VERSION "RCM"

NS_ :

BS_:

BU_: RCM ECU DASH

BO_ 768 RM0_Outputs: 8 RCM
 SG_ RM0_CH01_Out : 0|1@1+ (1,0) [0|1] "" Vector__XXX
 SG_ RM0_CH02_Out : 1|1@1+ (1,0) [0|1] "" Vector__XXX
 SG_ RM0_CH03_Out : 2|1@1+ (1,0) [0|1] "" Vector__XXX
 SG_ RM0_CH04_Out : 3|1@1+ (1,0) [0|1] "" Vector__XXX
 SG_ RM0_CH05_Out : 4|1@1+ (1,0) [0|1] "" Vector__XXX
 SG_ RM0_CH06_Out : 5|1@1+ (1,0) [0|1] "" Vector__XXX
 SG_ RM0_CH07_Out : 6|1@1+ (1,0) [0|1] "" Vector__XXX
 SG_ RM0_CH08_Out : 7|1@1+ (1,0) [0|1] "" Vector__XXX
 SG_ RM0_CH09_Out : 8|1@1+ (1,0) [0|1] "" Vector__XXX
 SG_ RM0_CH10_Out : 9|1@1+ (1,0) [0|1] "" Vector__XXX
 SG_ RM0_CH11_Out : 10|1@1+ (1,0) [0|1] "" Vector__XXX
 SG_ RM0_CH12_Out : 11|1@1+ (1,0) [0|1] "" Vector__XXX
 SG_ RM0_CH13_Out : 12|1@1+ (1,0) [0|1] "" Vector__XXX
 SG_ RM0_CH14_Out : 13|1@1+ (1,0) [0|1] "" Vector__XXX
 SG_ RM0_CH15_Out : 14|1@1+ (1,0) [0|1] "" Vector__XXX
 SG_ RM0_CH16_Out : 15|1@1+ (1,0) [0|1] "" Vector__XXX
 SG_ RM0_CH17_Out : 16|1@1+ (1,0) [0|1] "" Vector__XXX
 SG_ RM0_CH18_Out : 17|1@1+ (1,0) [0|1] "" Vector__XXX
 SG_ RM0_CH19_Out : 18|1@1+ (1,0) [0|1] "" Vector__XXX
 SG_ RM0_CH20_Out : 19|1@1+ (1,0) [0|1] "" Vector__XXX
 SG_ RM0_CH21_Out : 20|1@1+ (1,0) [0|1] "" Vector__XXX
 SG_ RM0_OutputsEnabled : 24|1@1+ (1,0) [0|1] "" Vector__XXX
 SG_ RM0_Failsafe : 25|1@1+ (1,0) [0|1] "" Vector__XXX
 SG_ RM0_AnyFault : 26|1@1+ (1,0) [0|1] "" Vector__XXX
 SG_ RM0_ImuOk : 27|1@1+ (1,0) [0|1] "" Vector__XXX
 SG_ RM0_EepromOk : 28|1@1+ (1,0) [0|1] "" Vector__XXX
 SG_ RM0_RoleKeypad : 29|1@1+ (1,0) [0|1] "" Vector__XXX
 SG_ RM0_IgnitionOn : 30|1@1+ (1,0) [0|1] "" Vector__XXX
 SG_ RM0_Forced500k : 31|1@1+ (1,0) [0|1] "" Vector__XXX
 SG_ RM0_UptimeSec : 32|16@1+ (1,0) [0|65535] "s" Vector__XXX
 SG_ RM0_NodeId : 48|8@1+ (1,0) [0|7] "" Vector__XXX
 SG_ RM0_Seq : 56|8@1+ (1,0) [0|255] "" Vector__XXX

BO_ 769 RM0_Inputs: 8 RCM
 SG_ RM0_CH01_In : 0|1@1+ (1,0) [0|1] "" Vector__XXX
 SG_ RM0_CH02_In : 1|1@1+ (1,0) [0|1] "" Vector__XXX
 SG_ RM0_CH03_In : 2|1@1+ (1,0) [0|1] "" Vector__XXX
 SG_ RM0_CH04_In : 3|1@1+ (1,0) [0|1] "" Vector__XXX
 SG_ RM0_CH05_In : 4|1@1+ (1,0) [0|1] "" Vector__XXX
 SG_ RM0_CH06_In : 5|1@1+ (1,0) [0|1] "" Vector__XXX
 SG_ RM0_CH07_In : 6|1@1+ (1,0) [0|1] "" Vector__XXX
 SG_ RM0_CH08_In : 7|1@1+ (1,0) [0|1] "" Vector__XXX
 SG_ RM0_CH09_In : 8|1@1+ (1,0) [0|1] "" Vector__XXX
 SG_ RM0_CH10_In : 9|1@1+ (1,0) [0|1] "" Vector__XXX
 SG_ RM0_CH11_In : 10|1@1+ (1,0) [0|1] "" Vector__XXX
 SG_ RM0_CH12_In : 11|1@1+ (1,0) [0|1] "" Vector__XXX
 SG_ RM0_CH13_In : 12|1@1+ (1,0) [0|1] "" Vector__XXX
 SG_ RM0_CH14_In : 13|1@1+ (1,0) [0|1] "" Vector__XXX
 SG_ RM0_CH15_In : 14|1@1+ (1,0) [0|1] "" Vector__XXX
 SG_ RM0_CH16_In : 15|1@1+ (1,0) [0|1] "" Vector__XXX
 SG_ RM0_CH17_In : 16|1@1+ (1,0) [0|1] "" Vector__XXX
 SG_ RM0_CH18_In : 17|1@1+ (1,0) [0|1] "" Vector__XXX
 SG_ RM0_CH19_In : 18|1@1+ (1,0) [0|1] "" Vector__XXX
 SG_ RM0_CH20_In : 19|1@1+ (1,0) [0|1] "" Vector__XXX
 SG_ RM0_CH21_In : 20|1@1+ (1,0) [0|1] "" Vector__XXX
 SG_ RM0_Aux1 : 24|1@1+ (1,0) [0|1] "" Vector__XXX
 SG_ RM0_Aux2 : 25|1@1+ (1,0) [0|1] "" Vector__XXX
 SG_ RM0_Aux3 : 26|1@1+ (1,0) [0|1] "" Vector__XXX
 SG_ RM0_CH01_Sense : 32|1@1+ (1,0) [0|1] "" Vector__XXX
 SG_ RM0_CH02_Sense : 33|1@1+ (1,0) [0|1] "" Vector__XXX
 SG_ RM0_CH03_Sense : 34|1@1+ (1,0) [0|1] "" Vector__XXX
 SG_ RM0_CH04_Sense : 35|1@1+ (1,0) [0|1] "" Vector__XXX
 SG_ RM0_CH05_Sense : 36|1@1+ (1,0) [0|1] "" Vector__XXX
 SG_ RM0_CH06_Sense : 37|1@1+ (1,0) [0|1] "" Vector__XXX
 SG_ RM0_CH07_Sense : 38|1@1+ (1,0) [0|1] "" Vector__XXX
 SG_ RM0_CH08_Sense : 39|1@1+ (1,0) [0|1] "" Vector__XXX
 SG_ RM0_CH09_Sense : 40|1@1+ (1,0) [0|1] "" Vector__XXX
 SG_ RM0_CH10_Sense : 41|1@1+ (1,0) [0|1] "" Vector__XXX
 SG_ RM0_CH11_Sense : 42|1@1+ (1,0) [0|1] "" Vector__XXX
 SG_ RM0_CH12_Sense : 43|1@1+ (1,0) [0|1] "" Vector__XXX
 SG_ RM0_CH13_Sense : 44|1@1+ (1,0) [0|1] "" Vector__XXX
 SG_ RM0_CH14_Sense : 45|1@1+ (1,0) [0|1] "" Vector__XXX
 SG_ RM0_CH15_Sense : 46|1@1+ (1,0) [0|1] "" Vector__XXX
 SG_ RM0_CH16_Sense : 47|1@1+ (1,0) [0|1] "" Vector__XXX
 SG_ RM0_CH17_Sense : 48|1@1+ (1,0) [0|1] "" Vector__XXX
 SG_ RM0_CH18_Sense : 49|1@1+ (1,0) [0|1] "" Vector__XXX
 SG_ RM0_CH19_Sense : 50|1@1+ (1,0) [0|1] "" Vector__XXX
 SG_ RM0_CH20_Sense : 51|1@1+ (1,0) [0|1] "" Vector__XXX
 SG_ RM0_CH21_Sense : 52|1@1+ (1,0) [0|1] "" Vector__XXX
 SG_ RM0_InSeq : 56|8@1+ (1,0) [0|255] "" Vector__XXX

BO_ 770 RM0_Faults: 8 RCM
 SG_ RM0_CH01_Open : 0|1@1+ (1,0) [0|1] "" Vector__XXX
 SG_ RM0_CH02_Open : 1|1@1+ (1,0) [0|1] "" Vector__XXX
 SG_ RM0_CH03_Open : 2|1@1+ (1,0) [0|1] "" Vector__XXX
 SG_ RM0_CH04_Open : 3|1@1+ (1,0) [0|1] "" Vector__XXX
 SG_ RM0_CH05_Open : 4|1@1+ (1,0) [0|1] "" Vector__XXX
 SG_ RM0_CH06_Open : 5|1@1+ (1,0) [0|1] "" Vector__XXX
 SG_ RM0_CH07_Open : 6|1@1+ (1,0) [0|1] "" Vector__XXX
 SG_ RM0_CH08_Open : 7|1@1+ (1,0) [0|1] "" Vector__XXX
 SG_ RM0_CH09_Open : 8|1@1+ (1,0) [0|1] "" Vector__XXX
 SG_ RM0_CH10_Open : 9|1@1+ (1,0) [0|1] "" Vector__XXX
 SG_ RM0_CH11_Open : 10|1@1+ (1,0) [0|1] "" Vector__XXX
 SG_ RM0_CH12_Open : 11|1@1+ (1,0) [0|1] "" Vector__XXX
 SG_ RM0_CH13_Open : 12|1@1+ (1,0) [0|1] "" Vector__XXX
 SG_ RM0_CH14_Open : 13|1@1+ (1,0) [0|1] "" Vector__XXX
 SG_ RM0_CH15_Open : 14|1@1+ (1,0) [0|1] "" Vector__XXX
 SG_ RM0_CH16_Open : 15|1@1+ (1,0) [0|1] "" Vector__XXX
 SG_ RM0_CH17_Open : 16|1@1+ (1,0) [0|1] "" Vector__XXX
 SG_ RM0_CH18_Open : 17|1@1+ (1,0) [0|1] "" Vector__XXX
 SG_ RM0_CH19_Open : 18|1@1+ (1,0) [0|1] "" Vector__XXX
 SG_ RM0_CH20_Open : 19|1@1+ (1,0) [0|1] "" Vector__XXX
 SG_ RM0_CH21_Open : 20|1@1+ (1,0) [0|1] "" Vector__XXX
 SG_ RM0_CH01_Short : 24|1@1+ (1,0) [0|1] "" Vector__XXX
 SG_ RM0_CH02_Short : 25|1@1+ (1,0) [0|1] "" Vector__XXX
 SG_ RM0_CH03_Short : 26|1@1+ (1,0) [0|1] "" Vector__XXX
 SG_ RM0_CH04_Short : 27|1@1+ (1,0) [0|1] "" Vector__XXX
 SG_ RM0_CH05_Short : 28|1@1+ (1,0) [0|1] "" Vector__XXX
 SG_ RM0_CH06_Short : 29|1@1+ (1,0) [0|1] "" Vector__XXX
 SG_ RM0_CH07_Short : 30|1@1+ (1,0) [0|1] "" Vector__XXX
 SG_ RM0_CH08_Short : 31|1@1+ (1,0) [0|1] "" Vector__XXX
 SG_ RM0_CH09_Short : 32|1@1+ (1,0) [0|1] "" Vector__XXX
 SG_ RM0_CH10_Short : 33|1@1+ (1,0) [0|1] "" Vector__XXX
 SG_ RM0_CH11_Short : 34|1@1+ (1,0) [0|1] "" Vector__XXX
 SG_ RM0_CH12_Short : 35|1@1+ (1,0) [0|1] "" Vector__XXX
 SG_ RM0_CH13_Short : 36|1@1+ (1,0) [0|1] "" Vector__XXX
 SG_ RM0_CH14_Short : 37|1@1+ (1,0) [0|1] "" Vector__XXX
 SG_ RM0_CH15_Short : 38|1@1+ (1,0) [0|1] "" Vector__XXX
 SG_ RM0_CH16_Short : 39|1@1+ (1,0) [0|1] "" Vector__XXX
 SG_ RM0_CH17_Short : 40|1@1+ (1,0) [0|1] "" Vector__XXX
 SG_ RM0_CH18_Short : 41|1@1+ (1,0) [0|1] "" Vector__XXX
 SG_ RM0_CH19_Short : 42|1@1+ (1,0) [0|1] "" Vector__XXX
 SG_ RM0_CH20_Short : 43|1@1+ (1,0) [0|1] "" Vector__XXX
 SG_ RM0_CH21_Short : 44|1@1+ (1,0) [0|1] "" Vector__XXX
 SG_ RM0_FaultSeq : 56|8@1+ (1,0) [0|255] "" Vector__XXX

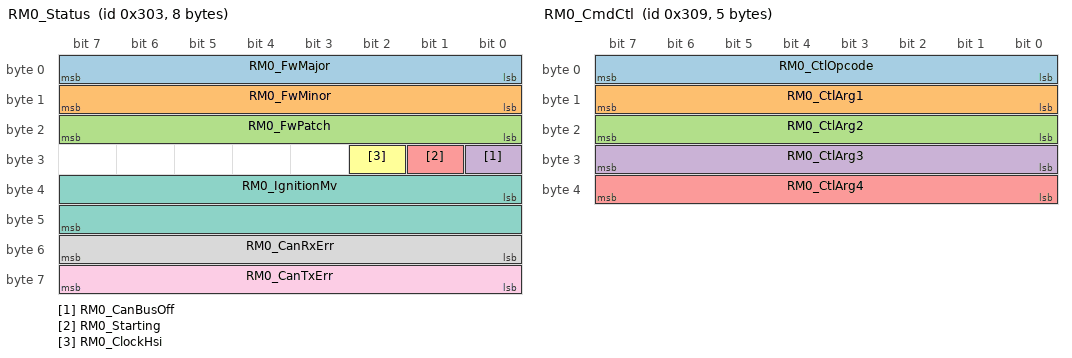
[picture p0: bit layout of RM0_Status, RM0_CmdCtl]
BO_ 771 RM0_Status: 8 RCM
 SG_ RM0_FwMajor : 0|8@1+ (1,0) [0|255] "" Vector__XXX
 SG_ RM0_FwMinor : 8|8@1+ (1,0) [0|255] "" Vector__XXX
 SG_ RM0_FwPatch : 16|8@1+ (1,0) [0|255] "" Vector__XXX
 SG_ RM0_CanBusOff : 24|1@1+ (1,0) [0|1] "" Vector__XXX
 SG_ RM0_Starting : 25|1@1+ (1,0) [0|1] "" Vector__XXX
 SG_ RM0_ClockHsi : 26|1@1+ (1,0) [0|1] "" Vector__XXX
 SG_ RM0_IgnitionMv : 32|16@1+ (1,0) [0|65535] "mV" Vector__XXX
 SG_ RM0_CanRxErr : 48|8@1+ (1,0) [0|255] "" Vector__XXX
 SG_ RM0_CanTxErr : 56|8@1+ (1,0) [0|255] "" Vector__XXX

BO_ 776 RM0_CmdSet: 6 ECU
 SG_ RM0_SetMask01 : 0|1@1+ (1,0) [0|1] "" Vector__XXX
 SG_ RM0_SetMask02 : 1|1@1+ (1,0) [0|1] "" Vector__XXX
 SG_ RM0_SetMask03 : 2|1@1+ (1,0) [0|1] "" Vector__XXX
 SG_ RM0_SetMask04 : 3|1@1+ (1,0) [0|1] "" Vector__XXX
 SG_ RM0_SetMask05 : 4|1@1+ (1,0) [0|1] "" Vector__XXX
 SG_ RM0_SetMask06 : 5|1@1+ (1,0) [0|1] "" Vector__XXX
 SG_ RM0_SetMask07 : 6|1@1+ (1,0) [0|1] "" Vector__XXX
 SG_ RM0_SetMask08 : 7|1@1+ (1,0) [0|1] "" Vector__XXX
 SG_ RM0_SetMask09 : 8|1@1+ (1,0) [0|1] "" Vector__XXX
 SG_ RM0_SetMask10 : 9|1@1+ (1,0) [0|1] "" Vector__XXX
 SG_ RM0_SetMask11 : 10|1@1+ (1,0) [0|1] "" Vector__XXX
 SG_ RM0_SetMask12 : 11|1@1+ (1,0) [0|1] "" Vector__XXX
 SG_ RM0_SetMask13 : 12|1@1+ (1,0) [0|1] "" Vector__XXX
 SG_ RM0_SetMask14 : 13|1@1+ (1,0) [0|1] "" Vector__XXX
 SG_ RM0_SetMask15 : 14|1@1+ (1,0) [0|1] "" Vector__XXX
 SG_ RM0_SetMask16 : 15|1@1+ (1,0) [0|1] "" Vector__XXX
 SG_ RM0_SetMask17 : 16|1@1+ (1,0) [0|1] "" Vector__XXX
 SG_ RM0_SetMask18 : 17|1@1+ (1,0) [0|1] "" Vector__XXX
 SG_ RM0_SetMask19 : 18|1@1+ (1,0) [0|1] "" Vector__XXX
 SG_ RM0_SetMask20 : 19|1@1+ (1,0) [0|1] "" Vector__XXX
 SG_ RM0_SetMask21 : 20|1@1+ (1,0) [0|1] "" Vector__XXX
 SG_ RM0_SetVal01 : 24|1@1+ (1,0) [0|1] "" Vector__XXX
 SG_ RM0_SetVal02 : 25|1@1+ (1,0) [0|1] "" Vector__XXX
 SG_ RM0_SetVal03 : 26|1@1+ (1,0) [0|1] "" Vector__XXX
 SG_ RM0_SetVal04 : 27|1@1+ (1,0) [0|1] "" Vector__XXX
 SG_ RM0_SetVal05 : 28|1@1+ (1,0) [0|1] "" Vector__XXX
 SG_ RM0_SetVal06 : 29|1@1+ (1,0) [0|1] "" Vector__XXX
 SG_ RM0_SetVal07 : 30|1@1+ (1,0) [0|1] "" Vector__XXX
 SG_ RM0_SetVal08 : 31|1@1+ (1,0) [0|1] "" Vector__XXX
 SG_ RM0_SetVal09 : 32|1@1+ (1,0) [0|1] "" Vector__XXX
 SG_ RM0_SetVal10 : 33|1@1+ (1,0) [0|1] "" Vector__XXX
 SG_ RM0_SetVal11 : 34|1@1+ (1,0) [0|1] "" Vector__XXX
 SG_ RM0_SetVal12 : 35|1@1+ (1,0) [0|1] "" Vector__XXX
 SG_ RM0_SetVal13 : 36|1@1+ (1,0) [0|1] "" Vector__XXX
 SG_ RM0_SetVal14 : 37|1@1+ (1,0) [0|1] "" Vector__XXX
 SG_ RM0_SetVal15 : 38|1@1+ (1,0) [0|1] "" Vector__XXX
 SG_ RM0_SetVal16 : 39|1@1+ (1,0) [0|1] "" Vector__XXX
 SG_ RM0_SetVal17 : 40|1@1+ (1,0) [0|1] "" Vector__XXX
 SG_ RM0_SetVal18 : 41|1@1+ (1,0) [0|1] "" Vector__XXX
 SG_ RM0_SetVal19 : 42|1@1+ (1,0) [0|1] "" Vector__XXX
 SG_ RM0_SetVal20 : 43|1@1+ (1,0) [0|1] "" Vector__XXX
 SG_ RM0_SetVal21 : 44|1@1+ (1,0) [0|1] "" Vector__XXX

BO_ 777 RM0_CmdCtl: 5 ECU
 SG_ RM0_CtlOpcode : 0|8@1+ (1,0) [0|255] "" Vector__XXX
 SG_ RM0_CtlArg1 : 8|8@1+ (1,0) [0|255] "" Vector__XXX
 SG_ RM0_CtlArg2 : 16|8@1+ (1,0) [0|255] "" Vector__XXX
 SG_ RM0_CtlArg3 : 24|8@1+ (1,0) [0|255] "" Vector__XXX
 SG_ RM0_CtlArg4 : 32|8@1+ (1,0) [0|255] "" Vector__XXX

BO_ 784 RM1_Outputs: 8 RCM
 SG_ RM1_CH01_Out : 0|1@1+ (1,0) [0|1] "" Vector__XXX
 SG_ RM1_CH02_Out : 1|1@1+ (1,0) [0|1] "" Vector__XXX
 SG_ RM1_CH03_Out : 2|1@1+ (1,0) [0|1] "" Vector__XXX
 SG_ RM1_CH04_Out : 3|1@1+ (1,0) [0|1] "" Vector__XXX
 SG_ RM1_CH05_Out : 4|1@1+ (1,0) [0|1] "" Vector__XXX
 SG_ RM1_CH06_Out : 5|1@1+ (1,0) [0|1] "" Vector__XXX
 SG_ RM1_CH07_Out : 6|1@1+ (1,0) [0|1] "" Vector__XXX
 SG_ RM1_CH08_Out : 7|1@1+ (1,0) [0|1] "" Vector__XXX
 SG_ RM1_CH09_Out : 8|1@1+ (1,0) [0|1] "" Vector__XXX
 SG_ RM1_CH10_Out : 9|1@1+ (1,0) [0|1] "" Vector__XXX
 SG_ RM1_CH11_Out : 10|1@1+ (1,0) [0|1] "" Vector__XXX
 SG_ RM1_CH12_Out : 11|1@1+ (1,0) [0|1] "" Vector__XXX
 SG_ RM1_CH13_Out : 12|1@1+ (1,0) [0|1] "" Vector__XXX
 SG_ RM1_CH14_Out : 13|1@1+ (1,0) [0|1] "" Vector__XXX
 SG_ RM1_CH15_Out : 14|1@1+ (1,0) [0|1] "" Vector__XXX
 SG_ RM1_CH16_Out : 15|1@1+ (1,0) [0|1] "" Vector__XXX
 SG_ RM1_CH17_Out : 16|1@1+ (1,0) [0|1] "" Vector__XXX
 SG_ RM1_CH18_Out : 17|1@1+ (1,0) [0|1] "" Vector__XXX
 SG_ RM1_CH19_Out : 18|1@1+ (1,0) [0|1] "" Vector__XXX
 SG_ RM1_CH20_Out : 19|1@1+ (1,0) [0|1] "" Vector__XXX
 SG_ RM1_CH21_Out : 20|1@1+ (1,0) [0|1] "" Vector__XXX
 SG_ RM1_OutputsEnabled : 24|1@1+ (1,0) [0|1] "" Vector__XXX
 SG_ RM1_Failsafe : 25|1@1+ (1,0) [0|1] "" Vector__XXX
 SG_ RM1_AnyFault : 26|1@1+ (1,0) [0|1] "" Vector__XXX
 SG_ RM1_ImuOk : 27|1@1+ (1,0) [0|1] "" Vector__XXX
 SG_ RM1_EepromOk : 28|1@1+ (1,0) [0|1] "" Vector__XXX
 SG_ RM1_RoleKeypad : 29|1@1+ (1,0) [0|1] "" Vector__XXX
 SG_ RM1_IgnitionOn : 30|1@1+ (1,0) [0|1] "" Vector__XXX
 SG_ RM1_Forced500k : 31|1@1+ (1,0) [0|1] "" Vector__XXX
 SG_ RM1_UptimeSec : 32|16@1+ (1,0) [0|65535] "s" Vector__XXX
 SG_ RM1_NodeId : 48|8@1+ (1,0) [0|7] "" Vector__XXX
 SG_ RM1_Seq : 56|8@1+ (1,0) [0|255] "" Vector__XXX

BO_ 785 RM1_Inputs: 8 RCM
 SG_ RM1_CH01_In : 0|1@1+ (1,0) [0|1] "" Vector__XXX
 SG_ RM1_CH02_In : 1|1@1+ (1,0) [0|1] "" Vector__XXX
 SG_ RM1_CH03_In : 2|1@1+ (1,0) [0|1] "" Vector__XXX
 SG_ RM1_CH04_In : 3|1@1+ (1,0) [0|1] "" Vector__XXX
 SG_ RM1_CH05_In : 4|1@1+ (1,0) [0|1] "" Vector__XXX
 SG_ RM1_CH06_In : 5|1@1+ (1,0) [0|1] "" Vector__XXX
 SG_ RM1_CH07_In : 6|1@1+ (1,0) [0|1] "" Vector__XXX
 SG_ RM1_CH08_In : 7|1@1+ (1,0) [0|1] "" Vector__XXX
 SG_ RM1_CH09_In : 8|1@1+ (1,0) [0|1] "" Vector__XXX
 SG_ RM1_CH10_In : 9|1@1+ (1,0) [0|1] "" Vector__XXX
 SG_ RM1_CH11_In : 10|1@1+ (1,0) [0|1] "" Vector__XXX
 SG_ RM1_CH12_In : 11|1@1+ (1,0) [0|1] "" Vector__XXX
 SG_ RM1_CH13_In : 12|1@1+ (1,0) [0|1] "" Vector__XXX
 SG_ RM1_CH14_In : 13|1@1+ (1,0) [0|1] "" Vector__XXX
 SG_ RM1_CH15_In : 14|1@1+ (1,0) [0|1] "" Vector__XXX
 SG_ RM1_CH16_In : 15|1@1+ (1,0) [0|1] "" Vector__XXX
 SG_ RM1_CH17_In : 16|1@1+ (1,0) [0|1] "" Vector__XXX
 SG_ RM1_CH18_In : 17|1@1+ (1,0) [0|1] "" Vector__XXX
 SG_ RM1_CH19_In : 18|1@1+ (1,0) [0|1] "" Vector__XXX
 SG_ RM1_CH20_In : 19|1@1+ (1,0) [0|1] "" Vector__XXX
 SG_ RM1_CH21_In : 20|1@1+ (1,0) [0|1] "" Vector__XXX
 SG_ RM1_Aux1 : 24|1@1+ (1,0) [0|1] "" Vector__XXX
 SG_ RM1_Aux2 : 25|1@1+ (1,0) [0|1] "" Vector__XXX
 SG_ RM1_Aux3 : 26|1@1+ (1,0) [0|1] "" Vector__XXX
 SG_ RM1_CH01_Sense : 32|1@1+ (1,0) [0|1] "" Vector__XXX
 SG_ RM1_CH02_Sense : 33|1@1+ (1,0) [0|1] "" Vector__XXX
 SG_ RM1_CH03_Sense : 34|1@1+ (1,0) [0|1] "" Vector__XXX
 SG_ RM1_CH04_Sense : 35|1@1+ (1,0) [0|1] "" Vector__XXX
 SG_ RM1_CH05_Sense : 36|1@1+ (1,0) [0|1] "" Vector__XXX
 SG_ RM1_CH06_Sense : 37|1@1+ (1,0) [0|1] "" Vector__XXX
 SG_ RM1_CH07_Sense : 38|1@1+ (1,0) [0|1] "" Vector__XXX
 SG_ RM1_CH08_Sense : 39|1@1+ (1,0) [0|1] "" Vector__XXX
 SG_ RM1_CH09_Sense : 40|1@1+ (1,0) [0|1] "" Vector__XXX
 SG_ RM1_CH10_Sense : 41|1@1+ (1,0) [0|1] "" Vector__XXX
 SG_ RM1_CH11_Sense : 42|1@1+ (1,0) [0|1] "" Vector__XXX
 SG_ RM1_CH12_Sense : 43|1@1+ (1,0) [0|1] "" Vector__XXX
 SG_ RM1_CH13_Sense : 44|1@1+ (1,0) [0|1] "" Vector__XXX
 SG_ RM1_CH14_Sense : 45|1@1+ (1,0) [0|1] "" Vector__XXX
 SG_ RM1_CH15_Sense : 46|1@1+ (1,0) [0|1] "" Vector__XXX
 SG_ RM1_CH16_Sense : 47|1@1+ (1,0) [0|1] "" Vector__XXX
 SG_ RM1_CH17_Sense : 48|1@1+ (1,0) [0|1] "" Vector__XXX
 SG_ RM1_CH18_Sense : 49|1@1+ (1,0) [0|1] "" Vector__XXX
 SG_ RM1_CH19_Sense : 50|1@1+ (1,0) [0|1] "" Vector__XXX
 SG_ RM1_CH20_Sense : 51|1@1+ (1,0) [0|1] "" Vector__XXX
 SG_ RM1_CH21_Sense : 52|1@1+ (1,0) [0|1] "" Vector__XXX
 SG_ RM1_InSeq : 56|8@1+ (1,0) [0|255] "" Vector__XXX

BO_ 786 RM1_Faults: 8 RCM
 SG_ RM1_CH01_Open : 0|1@1+ (1,0) [0|1] "" Vector__XXX
 SG_ RM1_CH02_Open : 1|1@1+ (1,0) [0|1] "" Vector__XXX
 SG_ RM1_CH03_Open : 2|1@1+ (1,0) [0|1] "" Vector__XXX
 SG_ RM1_CH04_Open : 3|1@1+ (1,0) [0|1] "" Vector__XXX
 SG_ RM1_CH05_Open : 4|1@1+ (1,0) [0|1] "" Vector__XXX
 SG_ RM1_CH06_Open : 5|1@1+ (1,0) [0|1] "" Vector__XXX
 SG_ RM1_CH07_Open : 6|1@1+ (1,0) [0|1] "" Vector__XXX
 SG_ RM1_CH08_Open : 7|1@1+ (1,0) [0|1] "" Vector__XXX
 SG_ RM1_CH09_Open : 8|1@1+ (1,0) [0|1] "" Vector__XXX
 SG_ RM1_CH10_Open : 9|1@1+ (1,0) [0|1] "" Vector__XXX
 SG_ RM1_CH11_Open : 10|1@1+ (1,0) [0|1] "" Vector__XXX
 SG_ RM1_CH12_Open : 11|1@1+ (1,0) [0|1] "" Vector__XXX
 SG_ RM1_CH13_Open : 12|1@1+ (1,0) [0|1] "" Vector__XXX
 SG_ RM1_CH14_Open : 13|1@1+ (1,0) [0|1] "" Vector__XXX
 SG_ RM1_CH15_Open : 14|1@1+ (1,0) [0|1] "" Vector__XXX
 SG_ RM1_CH16_Open : 15|1@1+ (1,0) [0|1] "" Vector__XXX
 SG_ RM1_CH17_Open : 16|1@1+ (1,0) [0|1] "" Vector__XXX
 SG_ RM1_CH18_Open : 17|1@1+ (1,0) [0|1] "" Vector__XXX
 SG_ RM1_CH19_Open : 18|1@1+ (1,0) [0|1] "" Vector__XXX
 SG_ RM1_CH20_Open : 19|1@1+ (1,0) [0|1] "" Vector__XXX
 SG_ RM1_CH21_Open : 20|1@1+ (1,0) [0|1] "" Vector__XXX
 SG_ RM1_CH01_Short : 24|1@1+ (1,0) [0|1] "" Vector__XXX
 SG_ RM1_CH02_Short : 25|1@1+ (1,0) [0|1] "" Vector__XXX
 SG_ RM1_CH03_Short : 26|1@1+ (1,0) [0|1] "" Vector__XXX
 SG_ RM1_CH04_Short : 27|1@1+ (1,0) [0|1] "" Vector__XXX
 SG_ RM1_CH05_Short : 28|1@1+ (1,0) [0|1] "" Vector__XXX
 SG_ RM1_CH06_Short : 29|1@1+ (1,0) [0|1] "" Vector__XXX
 SG_ RM1_CH07_Short : 30|1@1+ (1,0) [0|1] "" Vector__XXX
 SG_ RM1_CH08_Short : 31|1@1+ (1,0) [0|1] "" Vector__XXX
 SG_ RM1_CH09_Short : 32|1@1+ (1,0) [0|1] "" Vector__XXX
 SG_ RM1_CH10_Short : 33|1@1+ (1,0) [0|1] "" Vector__XXX
 SG_ RM1_CH11_Short : 34|1@1+ (1,0) [0|1] "" Vector__XXX
 SG_ RM1_CH12_Short : 35|1@1+ (1,0) [0|1] "" Vector__XXX
 SG_ RM1_CH13_Short : 36|1@1+ (1,0) [0|1] "" Vector__XXX
 SG_ RM1_CH14_Short : 37|1@1+ (1,0) [0|1] "" Vector__XXX
 SG_ RM1_CH15_Short : 38|1@1+ (1,0) [0|1] "" Vector__XXX
 SG_ RM1_CH16_Short : 39|1@1+ (1,0) [0|1] "" Vector__XXX
 SG_ RM1_CH17_Short : 40|1@1+ (1,0) [0|1] "" Vector__XXX
 SG_ RM1_CH18_Short : 41|1@1+ (1,0) [0|1] "" Vector__XXX
 SG_ RM1_CH19_Short : 42|1@1+ (1,0) [0|1] "" Vector__XXX
 SG_ RM1_CH20_Short : 43|1@1+ (1,0) [0|1] "" Vector__XXX
 SG_ RM1_CH21_Short : 44|1@1+ (1,0) [0|1] "" Vector__XXX
 SG_ RM1_FaultSeq : 56|8@1+ (1,0) [0|255] "" Vector__XXX

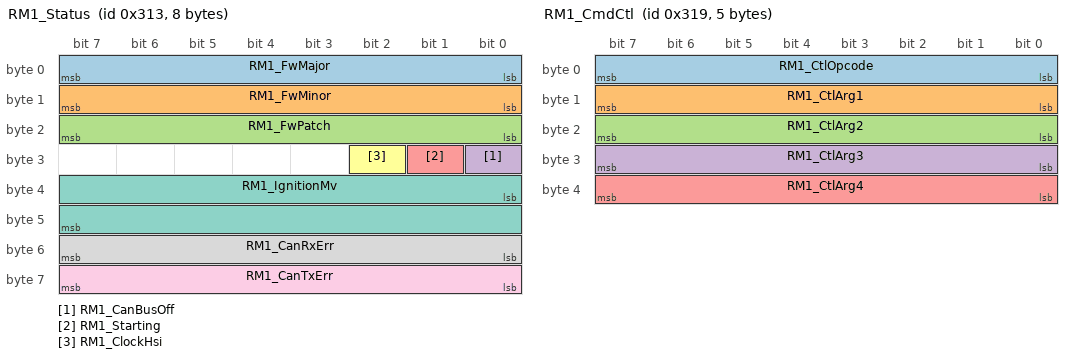
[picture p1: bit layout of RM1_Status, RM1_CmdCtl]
BO_ 787 RM1_Status: 8 RCM
 SG_ RM1_FwMajor : 0|8@1+ (1,0) [0|255] "" Vector__XXX
 SG_ RM1_FwMinor : 8|8@1+ (1,0) [0|255] "" Vector__XXX
 SG_ RM1_FwPatch : 16|8@1+ (1,0) [0|255] "" Vector__XXX
 SG_ RM1_CanBusOff : 24|1@1+ (1,0) [0|1] "" Vector__XXX
 SG_ RM1_Starting : 25|1@1+ (1,0) [0|1] "" Vector__XXX
 SG_ RM1_ClockHsi : 26|1@1+ (1,0) [0|1] "" Vector__XXX
 SG_ RM1_IgnitionMv : 32|16@1+ (1,0) [0|65535] "mV" Vector__XXX
 SG_ RM1_CanRxErr : 48|8@1+ (1,0) [0|255] "" Vector__XXX
 SG_ RM1_CanTxErr : 56|8@1+ (1,0) [0|255] "" Vector__XXX

BO_ 792 RM1_CmdSet: 6 ECU
 SG_ RM1_SetMask01 : 0|1@1+ (1,0) [0|1] "" Vector__XXX
 SG_ RM1_SetMask02 : 1|1@1+ (1,0) [0|1] "" Vector__XXX
 SG_ RM1_SetMask03 : 2|1@1+ (1,0) [0|1] "" Vector__XXX
 SG_ RM1_SetMask04 : 3|1@1+ (1,0) [0|1] "" Vector__XXX
 SG_ RM1_SetMask05 : 4|1@1+ (1,0) [0|1] "" Vector__XXX
 SG_ RM1_SetMask06 : 5|1@1+ (1,0) [0|1] "" Vector__XXX
 SG_ RM1_SetMask07 : 6|1@1+ (1,0) [0|1] "" Vector__XXX
 SG_ RM1_SetMask08 : 7|1@1+ (1,0) [0|1] "" Vector__XXX
 SG_ RM1_SetMask09 : 8|1@1+ (1,0) [0|1] "" Vector__XXX
 SG_ RM1_SetMask10 : 9|1@1+ (1,0) [0|1] "" Vector__XXX
 SG_ RM1_SetMask11 : 10|1@1+ (1,0) [0|1] "" Vector__XXX
 SG_ RM1_SetMask12 : 11|1@1+ (1,0) [0|1] "" Vector__XXX
 SG_ RM1_SetMask13 : 12|1@1+ (1,0) [0|1] "" Vector__XXX
 SG_ RM1_SetMask14 : 13|1@1+ (1,0) [0|1] "" Vector__XXX
 SG_ RM1_SetMask15 : 14|1@1+ (1,0) [0|1] "" Vector__XXX
 SG_ RM1_SetMask16 : 15|1@1+ (1,0) [0|1] "" Vector__XXX
 SG_ RM1_SetMask17 : 16|1@1+ (1,0) [0|1] "" Vector__XXX
 SG_ RM1_SetMask18 : 17|1@1+ (1,0) [0|1] "" Vector__XXX
 SG_ RM1_SetMask19 : 18|1@1+ (1,0) [0|1] "" Vector__XXX
 SG_ RM1_SetMask20 : 19|1@1+ (1,0) [0|1] "" Vector__XXX
 SG_ RM1_SetMask21 : 20|1@1+ (1,0) [0|1] "" Vector__XXX
 SG_ RM1_SetVal01 : 24|1@1+ (1,0) [0|1] "" Vector__XXX
 SG_ RM1_SetVal02 : 25|1@1+ (1,0) [0|1] "" Vector__XXX
 SG_ RM1_SetVal03 : 26|1@1+ (1,0) [0|1] "" Vector__XXX
 SG_ RM1_SetVal04 : 27|1@1+ (1,0) [0|1] "" Vector__XXX
 SG_ RM1_SetVal05 : 28|1@1+ (1,0) [0|1] "" Vector__XXX
 SG_ RM1_SetVal06 : 29|1@1+ (1,0) [0|1] "" Vector__XXX
 SG_ RM1_SetVal07 : 30|1@1+ (1,0) [0|1] "" Vector__XXX
 SG_ RM1_SetVal08 : 31|1@1+ (1,0) [0|1] "" Vector__XXX
 SG_ RM1_SetVal09 : 32|1@1+ (1,0) [0|1] "" Vector__XXX
 SG_ RM1_SetVal10 : 33|1@1+ (1,0) [0|1] "" Vector__XXX
 SG_ RM1_SetVal11 : 34|1@1+ (1,0) [0|1] "" Vector__XXX
 SG_ RM1_SetVal12 : 35|1@1+ (1,0) [0|1] "" Vector__XXX
 SG_ RM1_SetVal13 : 36|1@1+ (1,0) [0|1] "" Vector__XXX
 SG_ RM1_SetVal14 : 37|1@1+ (1,0) [0|1] "" Vector__XXX
 SG_ RM1_SetVal15 : 38|1@1+ (1,0) [0|1] "" Vector__XXX
 SG_ RM1_SetVal16 : 39|1@1+ (1,0) [0|1] "" Vector__XXX
 SG_ RM1_SetVal17 : 40|1@1+ (1,0) [0|1] "" Vector__XXX
 SG_ RM1_SetVal18 : 41|1@1+ (1,0) [0|1] "" Vector__XXX
 SG_ RM1_SetVal19 : 42|1@1+ (1,0) [0|1] "" Vector__XXX
 SG_ RM1_SetVal20 : 43|1@1+ (1,0) [0|1] "" Vector__XXX
 SG_ RM1_SetVal21 : 44|1@1+ (1,0) [0|1] "" Vector__XXX

BO_ 793 RM1_CmdCtl: 5 ECU
 SG_ RM1_CtlOpcode : 0|8@1+ (1,0) [0|255] "" Vector__XXX
 SG_ RM1_CtlArg1 : 8|8@1+ (1,0) [0|255] "" Vector__XXX
 SG_ RM1_CtlArg2 : 16|8@1+ (1,0) [0|255] "" Vector__XXX
 SG_ RM1_CtlArg3 : 24|8@1+ (1,0) [0|255] "" Vector__XXX
 SG_ RM1_CtlArg4 : 32|8@1+ (1,0) [0|255] "" Vector__XXX

BO_ 800 RM2_Outputs: 8 RCM
 SG_ RM2_CH01_Out : 0|1@1+ (1,0) [0|1] "" Vector__XXX
 SG_ RM2_CH02_Out : 1|1@1+ (1,0) [0|1] "" Vector__XXX
 SG_ RM2_CH03_Out : 2|1@1+ (1,0) [0|1] "" Vector__XXX
 SG_ RM2_CH04_Out : 3|1@1+ (1,0) [0|1] "" Vector__XXX
 SG_ RM2_CH05_Out : 4|1@1+ (1,0) [0|1] "" Vector__XXX
 SG_ RM2_CH06_Out : 5|1@1+ (1,0) [0|1] "" Vector__XXX
 SG_ RM2_CH07_Out : 6|1@1+ (1,0) [0|1] "" Vector__XXX
 SG_ RM2_CH08_Out : 7|1@1+ (1,0) [0|1] "" Vector__XXX
 SG_ RM2_CH09_Out : 8|1@1+ (1,0) [0|1] "" Vector__XXX
 SG_ RM2_CH10_Out : 9|1@1+ (1,0) [0|1] "" Vector__XXX
 SG_ RM2_CH11_Out : 10|1@1+ (1,0) [0|1] "" Vector__XXX
 SG_ RM2_CH12_Out : 11|1@1+ (1,0) [0|1] "" Vector__XXX
 SG_ RM2_CH13_Out : 12|1@1+ (1,0) [0|1] "" Vector__XXX
 SG_ RM2_CH14_Out : 13|1@1+ (1,0) [0|1] "" Vector__XXX
 SG_ RM2_CH15_Out : 14|1@1+ (1,0) [0|1] "" Vector__XXX
 SG_ RM2_CH16_Out : 15|1@1+ (1,0) [0|1] "" Vector__XXX
 SG_ RM2_CH17_Out : 16|1@1+ (1,0) [0|1] "" Vector__XXX
 SG_ RM2_CH18_Out : 17|1@1+ (1,0) [0|1] "" Vector__XXX
 SG_ RM2_CH19_Out : 18|1@1+ (1,0) [0|1] "" Vector__XXX
 SG_ RM2_CH20_Out : 19|1@1+ (1,0) [0|1] "" Vector__XXX
 SG_ RM2_CH21_Out : 20|1@1+ (1,0) [0|1] "" Vector__XXX
 SG_ RM2_OutputsEnabled : 24|1@1+ (1,0) [0|1] "" Vector__XXX
 SG_ RM2_Failsafe : 25|1@1+ (1,0) [0|1] "" Vector__XXX
 SG_ RM2_AnyFault : 26|1@1+ (1,0) [0|1] "" Vector__XXX
 SG_ RM2_ImuOk : 27|1@1+ (1,0) [0|1] "" Vector__XXX
 SG_ RM2_EepromOk : 28|1@1+ (1,0) [0|1] "" Vector__XXX
 SG_ RM2_RoleKeypad : 29|1@1+ (1,0) [0|1] "" Vector__XXX
 SG_ RM2_IgnitionOn : 30|1@1+ (1,0) [0|1] "" Vector__XXX
 SG_ RM2_Forced500k : 31|1@1+ (1,0) [0|1] "" Vector__XXX
 SG_ RM2_UptimeSec : 32|16@1+ (1,0) [0|65535] "s" Vector__XXX
 SG_ RM2_NodeId : 48|8@1+ (1,0) [0|7] "" Vector__XXX
 SG_ RM2_Seq : 56|8@1+ (1,0) [0|255] "" Vector__XXX

BO_ 801 RM2_Inputs: 8 RCM
 SG_ RM2_CH01_In : 0|1@1+ (1,0) [0|1] "" Vector__XXX
 SG_ RM2_CH02_In : 1|1@1+ (1,0) [0|1] "" Vector__XXX
 SG_ RM2_CH03_In : 2|1@1+ (1,0) [0|1] "" Vector__XXX
 SG_ RM2_CH04_In : 3|1@1+ (1,0) [0|1] "" Vector__XXX
 SG_ RM2_CH05_In : 4|1@1+ (1,0) [0|1] "" Vector__XXX
 SG_ RM2_CH06_In : 5|1@1+ (1,0) [0|1] "" Vector__XXX
 SG_ RM2_CH07_In : 6|1@1+ (1,0) [0|1] "" Vector__XXX
 SG_ RM2_CH08_In : 7|1@1+ (1,0) [0|1] "" Vector__XXX
 SG_ RM2_CH09_In : 8|1@1+ (1,0) [0|1] "" Vector__XXX
 SG_ RM2_CH10_In : 9|1@1+ (1,0) [0|1] "" Vector__XXX
 SG_ RM2_CH11_In : 10|1@1+ (1,0) [0|1] "" Vector__XXX
 SG_ RM2_CH12_In : 11|1@1+ (1,0) [0|1] "" Vector__XXX
 SG_ RM2_CH13_In : 12|1@1+ (1,0) [0|1] "" Vector__XXX
 SG_ RM2_CH14_In : 13|1@1+ (1,0) [0|1] "" Vector__XXX
 SG_ RM2_CH15_In : 14|1@1+ (1,0) [0|1] "" Vector__XXX
 SG_ RM2_CH16_In : 15|1@1+ (1,0) [0|1] "" Vector__XXX
 SG_ RM2_CH17_In : 16|1@1+ (1,0) [0|1] "" Vector__XXX
 SG_ RM2_CH18_In : 17|1@1+ (1,0) [0|1] "" Vector__XXX
 SG_ RM2_CH19_In : 18|1@1+ (1,0) [0|1] "" Vector__XXX
 SG_ RM2_CH20_In : 19|1@1+ (1,0) [0|1] "" Vector__XXX
 SG_ RM2_CH21_In : 20|1@1+ (1,0) [0|1] "" Vector__XXX
 SG_ RM2_Aux1 : 24|1@1+ (1,0) [0|1] "" Vector__XXX
 SG_ RM2_Aux2 : 25|1@1+ (1,0) [0|1] "" Vector__XXX
 SG_ RM2_Aux3 : 26|1@1+ (1,0) [0|1] "" Vector__XXX
 SG_ RM2_CH01_Sense : 32|1@1+ (1,0) [0|1] "" Vector__XXX
 SG_ RM2_CH02_Sense : 33|1@1+ (1,0) [0|1] "" Vector__XXX
 SG_ RM2_CH03_Sense : 34|1@1+ (1,0) [0|1] "" Vector__XXX
 SG_ RM2_CH04_Sense : 35|1@1+ (1,0) [0|1] "" Vector__XXX
 SG_ RM2_CH05_Sense : 36|1@1+ (1,0) [0|1] "" Vector__XXX
 SG_ RM2_CH06_Sense : 37|1@1+ (1,0) [0|1] "" Vector__XXX
 SG_ RM2_CH07_Sense : 38|1@1+ (1,0) [0|1] "" Vector__XXX
 SG_ RM2_CH08_Sense : 39|1@1+ (1,0) [0|1] "" Vector__XXX
 SG_ RM2_CH09_Sense : 40|1@1+ (1,0) [0|1] "" Vector__XXX
 SG_ RM2_CH10_Sense : 41|1@1+ (1,0) [0|1] "" Vector__XXX
 SG_ RM2_CH11_Sense : 42|1@1+ (1,0) [0|1] "" Vector__XXX
 SG_ RM2_CH12_Sense : 43|1@1+ (1,0) [0|1] "" Vector__XXX
 SG_ RM2_CH13_Sense : 44|1@1+ (1,0) [0|1] "" Vector__XXX
 SG_ RM2_CH14_Sense : 45|1@1+ (1,0) [0|1] "" Vector__XXX
 SG_ RM2_CH15_Sense : 46|1@1+ (1,0) [0|1] "" Vector__XXX
 SG_ RM2_CH16_Sense : 47|1@1+ (1,0) [0|1] "" Vector__XXX
 SG_ RM2_CH17_Sense : 48|1@1+ (1,0) [0|1] "" Vector__XXX
 SG_ RM2_CH18_Sense : 49|1@1+ (1,0) [0|1] "" Vector__XXX
 SG_ RM2_CH19_Sense : 50|1@1+ (1,0) [0|1] "" Vector__XXX
 SG_ RM2_CH20_Sense : 51|1@1+ (1,0) [0|1] "" Vector__XXX
 SG_ RM2_CH21_Sense : 52|1@1+ (1,0) [0|1] "" Vector__XXX
 SG_ RM2_InSeq : 56|8@1+ (1,0) [0|255] "" Vector__XXX

BO_ 802 RM2_Faults: 8 RCM
 SG_ RM2_CH01_Open : 0|1@1+ (1,0) [0|1] "" Vector__XXX
 SG_ RM2_CH02_Open : 1|1@1+ (1,0) [0|1] "" Vector__XXX
 SG_ RM2_CH03_Open : 2|1@1+ (1,0) [0|1] "" Vector__XXX
 SG_ RM2_CH04_Open : 3|1@1+ (1,0) [0|1] "" Vector__XXX
 SG_ RM2_CH05_Open : 4|1@1+ (1,0) [0|1] "" Vector__XXX
 SG_ RM2_CH06_Open : 5|1@1+ (1,0) [0|1] "" Vector__XXX
 SG_ RM2_CH07_Open : 6|1@1+ (1,0) [0|1] "" Vector__XXX
 SG_ RM2_CH08_Open : 7|1@1+ (1,0) [0|1] "" Vector__XXX
 SG_ RM2_CH09_Open : 8|1@1+ (1,0) [0|1] "" Vector__XXX
 SG_ RM2_CH10_Open : 9|1@1+ (1,0) [0|1] "" Vector__XXX
 SG_ RM2_CH11_Open : 10|1@1+ (1,0) [0|1] "" Vector__XXX
 SG_ RM2_CH12_Open : 11|1@1+ (1,0) [0|1] "" Vector__XXX
 SG_ RM2_CH13_Open : 12|1@1+ (1,0) [0|1] "" Vector__XXX
 SG_ RM2_CH14_Open : 13|1@1+ (1,0) [0|1] "" Vector__XXX
 SG_ RM2_CH15_Open : 14|1@1+ (1,0) [0|1] "" Vector__XXX
 SG_ RM2_CH16_Open : 15|1@1+ (1,0) [0|1] "" Vector__XXX
 SG_ RM2_CH17_Open : 16|1@1+ (1,0) [0|1] "" Vector__XXX
 SG_ RM2_CH18_Open : 17|1@1+ (1,0) [0|1] "" Vector__XXX
 SG_ RM2_CH19_Open : 18|1@1+ (1,0) [0|1] "" Vector__XXX
 SG_ RM2_CH20_Open : 19|1@1+ (1,0) [0|1] "" Vector__XXX
 SG_ RM2_CH21_Open : 20|1@1+ (1,0) [0|1] "" Vector__XXX
 SG_ RM2_CH01_Short : 24|1@1+ (1,0) [0|1] "" Vector__XXX
 SG_ RM2_CH02_Short : 25|1@1+ (1,0) [0|1] "" Vector__XXX
 SG_ RM2_CH03_Short : 26|1@1+ (1,0) [0|1] "" Vector__XXX
 SG_ RM2_CH04_Short : 27|1@1+ (1,0) [0|1] "" Vector__XXX
 SG_ RM2_CH05_Short : 28|1@1+ (1,0) [0|1] "" Vector__XXX
 SG_ RM2_CH06_Short : 29|1@1+ (1,0) [0|1] "" Vector__XXX
 SG_ RM2_CH07_Short : 30|1@1+ (1,0) [0|1] "" Vector__XXX
 SG_ RM2_CH08_Short : 31|1@1+ (1,0) [0|1] "" Vector__XXX
 SG_ RM2_CH09_Short : 32|1@1+ (1,0) [0|1] "" Vector__XXX
 SG_ RM2_CH10_Short : 33|1@1+ (1,0) [0|1] "" Vector__XXX
 SG_ RM2_CH11_Short : 34|1@1+ (1,0) [0|1] "" Vector__XXX
 SG_ RM2_CH12_Short : 35|1@1+ (1,0) [0|1] "" Vector__XXX
 SG_ RM2_CH13_Short : 36|1@1+ (1,0) [0|1] "" Vector__XXX
 SG_ RM2_CH14_Short : 37|1@1+ (1,0) [0|1] "" Vector__XXX
 SG_ RM2_CH15_Short : 38|1@1+ (1,0) [0|1] "" Vector__XXX
 SG_ RM2_CH16_Short : 39|1@1+ (1,0) [0|1] "" Vector__XXX
 SG_ RM2_CH17_Short : 40|1@1+ (1,0) [0|1] "" Vector__XXX
 SG_ RM2_CH18_Short : 41|1@1+ (1,0) [0|1] "" Vector__XXX
 SG_ RM2_CH19_Short : 42|1@1+ (1,0) [0|1] "" Vector__XXX
 SG_ RM2_CH20_Short : 43|1@1+ (1,0) [0|1] "" Vector__XXX
 SG_ RM2_CH21_Short : 44|1@1+ (1,0) [0|1] "" Vector__XXX
 SG_ RM2_FaultSeq : 56|8@1+ (1,0) [0|255] "" Vector__XXX

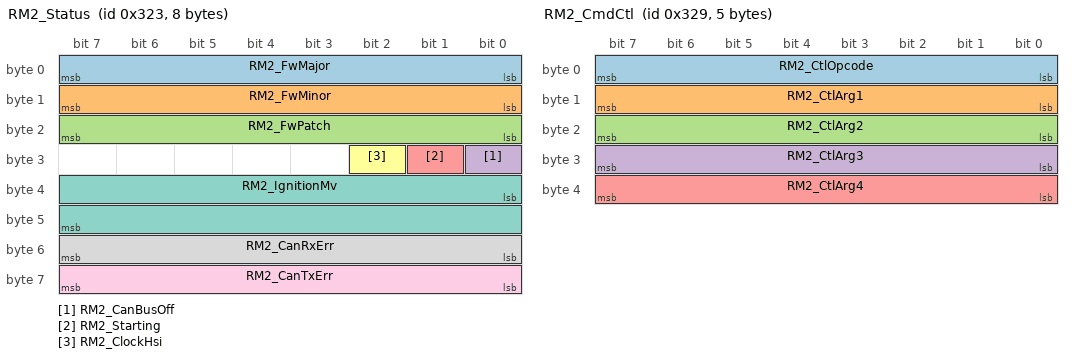
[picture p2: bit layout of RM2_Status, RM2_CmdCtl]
BO_ 803 RM2_Status: 8 RCM
 SG_ RM2_FwMajor : 0|8@1+ (1,0) [0|255] "" Vector__XXX
 SG_ RM2_FwMinor : 8|8@1+ (1,0) [0|255] "" Vector__XXX
 SG_ RM2_FwPatch : 16|8@1+ (1,0) [0|255] "" Vector__XXX
 SG_ RM2_CanBusOff : 24|1@1+ (1,0) [0|1] "" Vector__XXX
 SG_ RM2_Starting : 25|1@1+ (1,0) [0|1] "" Vector__XXX
 SG_ RM2_ClockHsi : 26|1@1+ (1,0) [0|1] "" Vector__XXX
 SG_ RM2_IgnitionMv : 32|16@1+ (1,0) [0|65535] "mV" Vector__XXX
 SG_ RM2_CanRxErr : 48|8@1+ (1,0) [0|255] "" Vector__XXX
 SG_ RM2_CanTxErr : 56|8@1+ (1,0) [0|255] "" Vector__XXX

BO_ 808 RM2_CmdSet: 6 ECU
 SG_ RM2_SetMask01 : 0|1@1+ (1,0) [0|1] "" Vector__XXX
 SG_ RM2_SetMask02 : 1|1@1+ (1,0) [0|1] "" Vector__XXX
 SG_ RM2_SetMask03 : 2|1@1+ (1,0) [0|1] "" Vector__XXX
 SG_ RM2_SetMask04 : 3|1@1+ (1,0) [0|1] "" Vector__XXX
 SG_ RM2_SetMask05 : 4|1@1+ (1,0) [0|1] "" Vector__XXX
 SG_ RM2_SetMask06 : 5|1@1+ (1,0) [0|1] "" Vector__XXX
 SG_ RM2_SetMask07 : 6|1@1+ (1,0) [0|1] "" Vector__XXX
 SG_ RM2_SetMask08 : 7|1@1+ (1,0) [0|1] "" Vector__XXX
 SG_ RM2_SetMask09 : 8|1@1+ (1,0) [0|1] "" Vector__XXX
 SG_ RM2_SetMask10 : 9|1@1+ (1,0) [0|1] "" Vector__XXX
 SG_ RM2_SetMask11 : 10|1@1+ (1,0) [0|1] "" Vector__XXX
 SG_ RM2_SetMask12 : 11|1@1+ (1,0) [0|1] "" Vector__XXX
 SG_ RM2_SetMask13 : 12|1@1+ (1,0) [0|1] "" Vector__XXX
 SG_ RM2_SetMask14 : 13|1@1+ (1,0) [0|1] "" Vector__XXX
 SG_ RM2_SetMask15 : 14|1@1+ (1,0) [0|1] "" Vector__XXX
 SG_ RM2_SetMask16 : 15|1@1+ (1,0) [0|1] "" Vector__XXX
 SG_ RM2_SetMask17 : 16|1@1+ (1,0) [0|1] "" Vector__XXX
 SG_ RM2_SetMask18 : 17|1@1+ (1,0) [0|1] "" Vector__XXX
 SG_ RM2_SetMask19 : 18|1@1+ (1,0) [0|1] "" Vector__XXX
 SG_ RM2_SetMask20 : 19|1@1+ (1,0) [0|1] "" Vector__XXX
 SG_ RM2_SetMask21 : 20|1@1+ (1,0) [0|1] "" Vector__XXX
 SG_ RM2_SetVal01 : 24|1@1+ (1,0) [0|1] "" Vector__XXX
 SG_ RM2_SetVal02 : 25|1@1+ (1,0) [0|1] "" Vector__XXX
 SG_ RM2_SetVal03 : 26|1@1+ (1,0) [0|1] "" Vector__XXX
 SG_ RM2_SetVal04 : 27|1@1+ (1,0) [0|1] "" Vector__XXX
 SG_ RM2_SetVal05 : 28|1@1+ (1,0) [0|1] "" Vector__XXX
 SG_ RM2_SetVal06 : 29|1@1+ (1,0) [0|1] "" Vector__XXX
 SG_ RM2_SetVal07 : 30|1@1+ (1,0) [0|1] "" Vector__XXX
 SG_ RM2_SetVal08 : 31|1@1+ (1,0) [0|1] "" Vector__XXX
 SG_ RM2_SetVal09 : 32|1@1+ (1,0) [0|1] "" Vector__XXX
 SG_ RM2_SetVal10 : 33|1@1+ (1,0) [0|1] "" Vector__XXX
 SG_ RM2_SetVal11 : 34|1@1+ (1,0) [0|1] "" Vector__XXX
 SG_ RM2_SetVal12 : 35|1@1+ (1,0) [0|1] "" Vector__XXX
 SG_ RM2_SetVal13 : 36|1@1+ (1,0) [0|1] "" Vector__XXX
 SG_ RM2_SetVal14 : 37|1@1+ (1,0) [0|1] "" Vector__XXX
 SG_ RM2_SetVal15 : 38|1@1+ (1,0) [0|1] "" Vector__XXX
 SG_ RM2_SetVal16 : 39|1@1+ (1,0) [0|1] "" Vector__XXX
 SG_ RM2_SetVal17 : 40|1@1+ (1,0) [0|1] "" Vector__XXX
 SG_ RM2_SetVal18 : 41|1@1+ (1,0) [0|1] "" Vector__XXX
 SG_ RM2_SetVal19 : 42|1@1+ (1,0) [0|1] "" Vector__XXX
 SG_ RM2_SetVal20 : 43|1@1+ (1,0) [0|1] "" Vector__XXX
 SG_ RM2_SetVal21 : 44|1@1+ (1,0) [0|1] "" Vector__XXX

BO_ 809 RM2_CmdCtl: 5 ECU
 SG_ RM2_CtlOpcode : 0|8@1+ (1,0) [0|255] "" Vector__XXX
 SG_ RM2_CtlArg1 : 8|8@1+ (1,0) [0|255] "" Vector__XXX
 SG_ RM2_CtlArg2 : 16|8@1+ (1,0) [0|255] "" Vector__XXX
 SG_ RM2_CtlArg3 : 24|8@1+ (1,0) [0|255] "" Vector__XXX
 SG_ RM2_CtlArg4 : 32|8@1+ (1,0) [0|255] "" Vector__XXX

BO_ 816 RM3_Outputs: 8 RCM
 SG_ RM3_CH01_Out : 0|1@1+ (1,0) [0|1] "" Vector__XXX
 SG_ RM3_CH02_Out : 1|1@1+ (1,0) [0|1] "" Vector__XXX
 SG_ RM3_CH03_Out : 2|1@1+ (1,0) [0|1] "" Vector__XXX
 SG_ RM3_CH04_Out : 3|1@1+ (1,0) [0|1] "" Vector__XXX
 SG_ RM3_CH05_Out : 4|1@1+ (1,0) [0|1] "" Vector__XXX
 SG_ RM3_CH06_Out : 5|1@1+ (1,0) [0|1] "" Vector__XXX
 SG_ RM3_CH07_Out : 6|1@1+ (1,0) [0|1] "" Vector__XXX
 SG_ RM3_CH08_Out : 7|1@1+ (1,0) [0|1] "" Vector__XXX
 SG_ RM3_CH09_Out : 8|1@1+ (1,0) [0|1] "" Vector__XXX
 SG_ RM3_CH10_Out : 9|1@1+ (1,0) [0|1] "" Vector__XXX
 SG_ RM3_CH11_Out : 10|1@1+ (1,0) [0|1] "" Vector__XXX
 SG_ RM3_CH12_Out : 11|1@1+ (1,0) [0|1] "" Vector__XXX
 SG_ RM3_CH13_Out : 12|1@1+ (1,0) [0|1] "" Vector__XXX
 SG_ RM3_CH14_Out : 13|1@1+ (1,0) [0|1] "" Vector__XXX
 SG_ RM3_CH15_Out : 14|1@1+ (1,0) [0|1] "" Vector__XXX
 SG_ RM3_CH16_Out : 15|1@1+ (1,0) [0|1] "" Vector__XXX
 SG_ RM3_CH17_Out : 16|1@1+ (1,0) [0|1] "" Vector__XXX
 SG_ RM3_CH18_Out : 17|1@1+ (1,0) [0|1] "" Vector__XXX
 SG_ RM3_CH19_Out : 18|1@1+ (1,0) [0|1] "" Vector__XXX
 SG_ RM3_CH20_Out : 19|1@1+ (1,0) [0|1] "" Vector__XXX
 SG_ RM3_CH21_Out : 20|1@1+ (1,0) [0|1] "" Vector__XXX
 SG_ RM3_OutputsEnabled : 24|1@1+ (1,0) [0|1] "" Vector__XXX
 SG_ RM3_Failsafe : 25|1@1+ (1,0) [0|1] "" Vector__XXX
 SG_ RM3_AnyFault : 26|1@1+ (1,0) [0|1] "" Vector__XXX
 SG_ RM3_ImuOk : 27|1@1+ (1,0) [0|1] "" Vector__XXX
 SG_ RM3_EepromOk : 28|1@1+ (1,0) [0|1] "" Vector__XXX
 SG_ RM3_RoleKeypad : 29|1@1+ (1,0) [0|1] "" Vector__XXX
 SG_ RM3_IgnitionOn : 30|1@1+ (1,0) [0|1] "" Vector__XXX
 SG_ RM3_Forced500k : 31|1@1+ (1,0) [0|1] "" Vector__XXX
 SG_ RM3_UptimeSec : 32|16@1+ (1,0) [0|65535] "s" Vector__XXX
 SG_ RM3_NodeId : 48|8@1+ (1,0) [0|7] "" Vector__XXX
 SG_ RM3_Seq : 56|8@1+ (1,0) [0|255] "" Vector__XXX

BO_ 817 RM3_Inputs: 8 RCM
 SG_ RM3_CH01_In : 0|1@1+ (1,0) [0|1] "" Vector__XXX
 SG_ RM3_CH02_In : 1|1@1+ (1,0) [0|1] "" Vector__XXX
 SG_ RM3_CH03_In : 2|1@1+ (1,0) [0|1] "" Vector__XXX
 SG_ RM3_CH04_In : 3|1@1+ (1,0) [0|1] "" Vector__XXX
 SG_ RM3_CH05_In : 4|1@1+ (1,0) [0|1] "" Vector__XXX
 SG_ RM3_CH06_In : 5|1@1+ (1,0) [0|1] "" Vector__XXX
 SG_ RM3_CH07_In : 6|1@1+ (1,0) [0|1] "" Vector__XXX
 SG_ RM3_CH08_In : 7|1@1+ (1,0) [0|1] "" Vector__XXX
 SG_ RM3_CH09_In : 8|1@1+ (1,0) [0|1] "" Vector__XXX
 SG_ RM3_CH10_In : 9|1@1+ (1,0) [0|1] "" Vector__XXX
 SG_ RM3_CH11_In : 10|1@1+ (1,0) [0|1] "" Vector__XXX
 SG_ RM3_CH12_In : 11|1@1+ (1,0) [0|1] "" Vector__XXX
 SG_ RM3_CH13_In : 12|1@1+ (1,0) [0|1] "" Vector__XXX
 SG_ RM3_CH14_In : 13|1@1+ (1,0) [0|1] "" Vector__XXX
 SG_ RM3_CH15_In : 14|1@1+ (1,0) [0|1] "" Vector__XXX
 SG_ RM3_CH16_In : 15|1@1+ (1,0) [0|1] "" Vector__XXX
 SG_ RM3_CH17_In : 16|1@1+ (1,0) [0|1] "" Vector__XXX
 SG_ RM3_CH18_In : 17|1@1+ (1,0) [0|1] "" Vector__XXX
 SG_ RM3_CH19_In : 18|1@1+ (1,0) [0|1] "" Vector__XXX
 SG_ RM3_CH20_In : 19|1@1+ (1,0) [0|1] "" Vector__XXX
 SG_ RM3_CH21_In : 20|1@1+ (1,0) [0|1] "" Vector__XXX
 SG_ RM3_Aux1 : 24|1@1+ (1,0) [0|1] "" Vector__XXX
 SG_ RM3_Aux2 : 25|1@1+ (1,0) [0|1] "" Vector__XXX
 SG_ RM3_Aux3 : 26|1@1+ (1,0) [0|1] "" Vector__XXX
 SG_ RM3_CH01_Sense : 32|1@1+ (1,0) [0|1] "" Vector__XXX
 SG_ RM3_CH02_Sense : 33|1@1+ (1,0) [0|1] "" Vector__XXX
 SG_ RM3_CH03_Sense : 34|1@1+ (1,0) [0|1] "" Vector__XXX
 SG_ RM3_CH04_Sense : 35|1@1+ (1,0) [0|1] "" Vector__XXX
 SG_ RM3_CH05_Sense : 36|1@1+ (1,0) [0|1] "" Vector__XXX
 SG_ RM3_CH06_Sense : 37|1@1+ (1,0) [0|1] "" Vector__XXX
 SG_ RM3_CH07_Sense : 38|1@1+ (1,0) [0|1] "" Vector__XXX
 SG_ RM3_CH08_Sense : 39|1@1+ (1,0) [0|1] "" Vector__XXX
 SG_ RM3_CH09_Sense : 40|1@1+ (1,0) [0|1] "" Vector__XXX
 SG_ RM3_CH10_Sense : 41|1@1+ (1,0) [0|1] "" Vector__XXX
 SG_ RM3_CH11_Sense : 42|1@1+ (1,0) [0|1] "" Vector__XXX
 SG_ RM3_CH12_Sense : 43|1@1+ (1,0) [0|1] "" Vector__XXX
 SG_ RM3_CH13_Sense : 44|1@1+ (1,0) [0|1] "" Vector__XXX
 SG_ RM3_CH14_Sense : 45|1@1+ (1,0) [0|1] "" Vector__XXX
 SG_ RM3_CH15_Sense : 46|1@1+ (1,0) [0|1] "" Vector__XXX
 SG_ RM3_CH16_Sense : 47|1@1+ (1,0) [0|1] "" Vector__XXX
 SG_ RM3_CH17_Sense : 48|1@1+ (1,0) [0|1] "" Vector__XXX
 SG_ RM3_CH18_Sense : 49|1@1+ (1,0) [0|1] "" Vector__XXX
 SG_ RM3_CH19_Sense : 50|1@1+ (1,0) [0|1] "" Vector__XXX
 SG_ RM3_CH20_Sense : 51|1@1+ (1,0) [0|1] "" Vector__XXX
 SG_ RM3_CH21_Sense : 52|1@1+ (1,0) [0|1] "" Vector__XXX
 SG_ RM3_InSeq : 56|8@1+ (1,0) [0|255] "" Vector__XXX

BO_ 818 RM3_Faults: 8 RCM
 SG_ RM3_CH01_Open : 0|1@1+ (1,0) [0|1] "" Vector__XXX
 SG_ RM3_CH02_Open : 1|1@1+ (1,0) [0|1] "" Vector__XXX
 SG_ RM3_CH03_Open : 2|1@1+ (1,0) [0|1] "" Vector__XXX
 SG_ RM3_CH04_Open : 3|1@1+ (1,0) [0|1] "" Vector__XXX
 SG_ RM3_CH05_Open : 4|1@1+ (1,0) [0|1] "" Vector__XXX
 SG_ RM3_CH06_Open : 5|1@1+ (1,0) [0|1] "" Vector__XXX
 SG_ RM3_CH07_Open : 6|1@1+ (1,0) [0|1] "" Vector__XXX
 SG_ RM3_CH08_Open : 7|1@1+ (1,0) [0|1] "" Vector__XXX
 SG_ RM3_CH09_Open : 8|1@1+ (1,0) [0|1] "" Vector__XXX
 SG_ RM3_CH10_Open : 9|1@1+ (1,0) [0|1] "" Vector__XXX
 SG_ RM3_CH11_Open : 10|1@1+ (1,0) [0|1] "" Vector__XXX
 SG_ RM3_CH12_Open : 11|1@1+ (1,0) [0|1] "" Vector__XXX
 SG_ RM3_CH13_Open : 12|1@1+ (1,0) [0|1] "" Vector__XXX
 SG_ RM3_CH14_Open : 13|1@1+ (1,0) [0|1] "" Vector__XXX
 SG_ RM3_CH15_Open : 14|1@1+ (1,0) [0|1] "" Vector__XXX
 SG_ RM3_CH16_Open : 15|1@1+ (1,0) [0|1] "" Vector__XXX
 SG_ RM3_CH17_Open : 16|1@1+ (1,0) [0|1] "" Vector__XXX
 SG_ RM3_CH18_Open : 17|1@1+ (1,0) [0|1] "" Vector__XXX
 SG_ RM3_CH19_Open : 18|1@1+ (1,0) [0|1] "" Vector__XXX
 SG_ RM3_CH20_Open : 19|1@1+ (1,0) [0|1] "" Vector__XXX
 SG_ RM3_CH21_Open : 20|1@1+ (1,0) [0|1] "" Vector__XXX
 SG_ RM3_CH01_Short : 24|1@1+ (1,0) [0|1] "" Vector__XXX
 SG_ RM3_CH02_Short : 25|1@1+ (1,0) [0|1] "" Vector__XXX
 SG_ RM3_CH03_Short : 26|1@1+ (1,0) [0|1] "" Vector__XXX
 SG_ RM3_CH04_Short : 27|1@1+ (1,0) [0|1] "" Vector__XXX
 SG_ RM3_CH05_Short : 28|1@1+ (1,0) [0|1] "" Vector__XXX
 SG_ RM3_CH06_Short : 29|1@1+ (1,0) [0|1] "" Vector__XXX
 SG_ RM3_CH07_Short : 30|1@1+ (1,0) [0|1] "" Vector__XXX
 SG_ RM3_CH08_Short : 31|1@1+ (1,0) [0|1] "" Vector__XXX
 SG_ RM3_CH09_Short : 32|1@1+ (1,0) [0|1] "" Vector__XXX
 SG_ RM3_CH10_Short : 33|1@1+ (1,0) [0|1] "" Vector__XXX
 SG_ RM3_CH11_Short : 34|1@1+ (1,0) [0|1] "" Vector__XXX
 SG_ RM3_CH12_Short : 35|1@1+ (1,0) [0|1] "" Vector__XXX
 SG_ RM3_CH13_Short : 36|1@1+ (1,0) [0|1] "" Vector__XXX
 SG_ RM3_CH14_Short : 37|1@1+ (1,0) [0|1] "" Vector__XXX
 SG_ RM3_CH15_Short : 38|1@1+ (1,0) [0|1] "" Vector__XXX
 SG_ RM3_CH16_Short : 39|1@1+ (1,0) [0|1] "" Vector__XXX
 SG_ RM3_CH17_Short : 40|1@1+ (1,0) [0|1] "" Vector__XXX
 SG_ RM3_CH18_Short : 41|1@1+ (1,0) [0|1] "" Vector__XXX
 SG_ RM3_CH19_Short : 42|1@1+ (1,0) [0|1] "" Vector__XXX
 SG_ RM3_CH20_Short : 43|1@1+ (1,0) [0|1] "" Vector__XXX
 SG_ RM3_CH21_Short : 44|1@1+ (1,0) [0|1] "" Vector__XXX
 SG_ RM3_FaultSeq : 56|8@1+ (1,0) [0|255] "" Vector__XXX

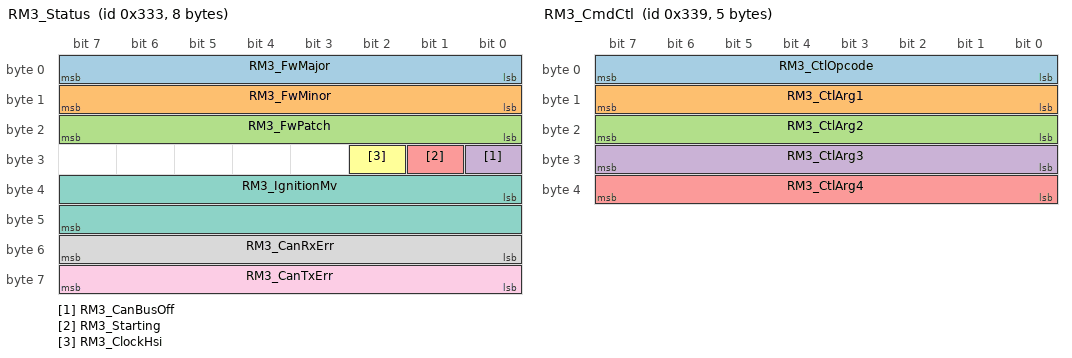
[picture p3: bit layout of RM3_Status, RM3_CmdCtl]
BO_ 819 RM3_Status: 8 RCM
 SG_ RM3_FwMajor : 0|8@1+ (1,0) [0|255] "" Vector__XXX
 SG_ RM3_FwMinor : 8|8@1+ (1,0) [0|255] "" Vector__XXX
 SG_ RM3_FwPatch : 16|8@1+ (1,0) [0|255] "" Vector__XXX
 SG_ RM3_CanBusOff : 24|1@1+ (1,0) [0|1] "" Vector__XXX
 SG_ RM3_Starting : 25|1@1+ (1,0) [0|1] "" Vector__XXX
 SG_ RM3_ClockHsi : 26|1@1+ (1,0) [0|1] "" Vector__XXX
 SG_ RM3_IgnitionMv : 32|16@1+ (1,0) [0|65535] "mV" Vector__XXX
 SG_ RM3_CanRxErr : 48|8@1+ (1,0) [0|255] "" Vector__XXX
 SG_ RM3_CanTxErr : 56|8@1+ (1,0) [0|255] "" Vector__XXX

BO_ 824 RM3_CmdSet: 6 ECU
 SG_ RM3_SetMask01 : 0|1@1+ (1,0) [0|1] "" Vector__XXX
 SG_ RM3_SetMask02 : 1|1@1+ (1,0) [0|1] "" Vector__XXX
 SG_ RM3_SetMask03 : 2|1@1+ (1,0) [0|1] "" Vector__XXX
 SG_ RM3_SetMask04 : 3|1@1+ (1,0) [0|1] "" Vector__XXX
 SG_ RM3_SetMask05 : 4|1@1+ (1,0) [0|1] "" Vector__XXX
 SG_ RM3_SetMask06 : 5|1@1+ (1,0) [0|1] "" Vector__XXX
 SG_ RM3_SetMask07 : 6|1@1+ (1,0) [0|1] "" Vector__XXX
 SG_ RM3_SetMask08 : 7|1@1+ (1,0) [0|1] "" Vector__XXX
 SG_ RM3_SetMask09 : 8|1@1+ (1,0) [0|1] "" Vector__XXX
 SG_ RM3_SetMask10 : 9|1@1+ (1,0) [0|1] "" Vector__XXX
 SG_ RM3_SetMask11 : 10|1@1+ (1,0) [0|1] "" Vector__XXX
 SG_ RM3_SetMask12 : 11|1@1+ (1,0) [0|1] "" Vector__XXX
 SG_ RM3_SetMask13 : 12|1@1+ (1,0) [0|1] "" Vector__XXX
 SG_ RM3_SetMask14 : 13|1@1+ (1,0) [0|1] "" Vector__XXX
 SG_ RM3_SetMask15 : 14|1@1+ (1,0) [0|1] "" Vector__XXX
 SG_ RM3_SetMask16 : 15|1@1+ (1,0) [0|1] "" Vector__XXX
 SG_ RM3_SetMask17 : 16|1@1+ (1,0) [0|1] "" Vector__XXX
 SG_ RM3_SetMask18 : 17|1@1+ (1,0) [0|1] "" Vector__XXX
 SG_ RM3_SetMask19 : 18|1@1+ (1,0) [0|1] "" Vector__XXX
 SG_ RM3_SetMask20 : 19|1@1+ (1,0) [0|1] "" Vector__XXX
 SG_ RM3_SetMask21 : 20|1@1+ (1,0) [0|1] "" Vector__XXX
 SG_ RM3_SetVal01 : 24|1@1+ (1,0) [0|1] "" Vector__XXX
 SG_ RM3_SetVal02 : 25|1@1+ (1,0) [0|1] "" Vector__XXX
 SG_ RM3_SetVal03 : 26|1@1+ (1,0) [0|1] "" Vector__XXX
 SG_ RM3_SetVal04 : 27|1@1+ (1,0) [0|1] "" Vector__XXX
 SG_ RM3_SetVal05 : 28|1@1+ (1,0) [0|1] "" Vector__XXX
 SG_ RM3_SetVal06 : 29|1@1+ (1,0) [0|1] "" Vector__XXX
 SG_ RM3_SetVal07 : 30|1@1+ (1,0) [0|1] "" Vector__XXX
 SG_ RM3_SetVal08 : 31|1@1+ (1,0) [0|1] "" Vector__XXX
 SG_ RM3_SetVal09 : 32|1@1+ (1,0) [0|1] "" Vector__XXX
 SG_ RM3_SetVal10 : 33|1@1+ (1,0) [0|1] "" Vector__XXX
 SG_ RM3_SetVal11 : 34|1@1+ (1,0) [0|1] "" Vector__XXX
 SG_ RM3_SetVal12 : 35|1@1+ (1,0) [0|1] "" Vector__XXX
 SG_ RM3_SetVal13 : 36|1@1+ (1,0) [0|1] "" Vector__XXX
 SG_ RM3_SetVal14 : 37|1@1+ (1,0) [0|1] "" Vector__XXX
 SG_ RM3_SetVal15 : 38|1@1+ (1,0) [0|1] "" Vector__XXX
 SG_ RM3_SetVal16 : 39|1@1+ (1,0) [0|1] "" Vector__XXX
 SG_ RM3_SetVal17 : 40|1@1+ (1,0) [0|1] "" Vector__XXX
 SG_ RM3_SetVal18 : 41|1@1+ (1,0) [0|1] "" Vector__XXX
 SG_ RM3_SetVal19 : 42|1@1+ (1,0) [0|1] "" Vector__XXX
 SG_ RM3_SetVal20 : 43|1@1+ (1,0) [0|1] "" Vector__XXX
 SG_ RM3_SetVal21 : 44|1@1+ (1,0) [0|1] "" Vector__XXX

BO_ 825 RM3_CmdCtl: 5 ECU
 SG_ RM3_CtlOpcode : 0|8@1+ (1,0) [0|255] "" Vector__XXX
 SG_ RM3_CtlArg1 : 8|8@1+ (1,0) [0|255] "" Vector__XXX
 SG_ RM3_CtlArg2 : 16|8@1+ (1,0) [0|255] "" Vector__XXX
 SG_ RM3_CtlArg3 : 24|8@1+ (1,0) [0|255] "" Vector__XXX
 SG_ RM3_CtlArg4 : 32|8@1+ (1,0) [0|255] "" Vector__XXX

BO_ 832 KP0_Outputs: 8 RCM
 SG_ KP0_CH01_Out : 0|1@1+ (1,0) [0|1] "" Vector__XXX
 SG_ KP0_CH02_Out : 1|1@1+ (1,0) [0|1] "" Vector__XXX
 SG_ KP0_CH03_Out : 2|1@1+ (1,0) [0|1] "" Vector__XXX
 SG_ KP0_CH04_Out : 3|1@1+ (1,0) [0|1] "" Vector__XXX
 SG_ KP0_CH05_Out : 4|1@1+ (1,0) [0|1] "" Vector__XXX
 SG_ KP0_CH06_Out : 5|1@1+ (1,0) [0|1] "" Vector__XXX
 SG_ KP0_CH07_Out : 6|1@1+ (1,0) [0|1] "" Vector__XXX
 SG_ KP0_CH08_Out : 7|1@1+ (1,0) [0|1] "" Vector__XXX
 SG_ KP0_CH09_Out : 8|1@1+ (1,0) [0|1] "" Vector__XXX
 SG_ KP0_CH10_Out : 9|1@1+ (1,0) [0|1] "" Vector__XXX
 SG_ KP0_CH11_Out : 10|1@1+ (1,0) [0|1] "" Vector__XXX
 SG_ KP0_CH12_Out : 11|1@1+ (1,0) [0|1] "" Vector__XXX
 SG_ KP0_CH13_Out : 12|1@1+ (1,0) [0|1] "" Vector__XXX
 SG_ KP0_CH14_Out : 13|1@1+ (1,0) [0|1] "" Vector__XXX
 SG_ KP0_CH15_Out : 14|1@1+ (1,0) [0|1] "" Vector__XXX
 SG_ KP0_CH16_Out : 15|1@1+ (1,0) [0|1] "" Vector__XXX
 SG_ KP0_CH17_Out : 16|1@1+ (1,0) [0|1] "" Vector__XXX
 SG_ KP0_CH18_Out : 17|1@1+ (1,0) [0|1] "" Vector__XXX
 SG_ KP0_CH19_Out : 18|1@1+ (1,0) [0|1] "" Vector__XXX
 SG_ KP0_CH20_Out : 19|1@1+ (1,0) [0|1] "" Vector__XXX
 SG_ KP0_CH21_Out : 20|1@1+ (1,0) [0|1] "" Vector__XXX
 SG_ KP0_OutputsEnabled : 24|1@1+ (1,0) [0|1] "" Vector__XXX
 SG_ KP0_Failsafe : 25|1@1+ (1,0) [0|1] "" Vector__XXX
 SG_ KP0_AnyFault : 26|1@1+ (1,0) [0|1] "" Vector__XXX
 SG_ KP0_ImuOk : 27|1@1+ (1,0) [0|1] "" Vector__XXX
 SG_ KP0_EepromOk : 28|1@1+ (1,0) [0|1] "" Vector__XXX
 SG_ KP0_RoleKeypad : 29|1@1+ (1,0) [0|1] "" Vector__XXX
 SG_ KP0_IgnitionOn : 30|1@1+ (1,0) [0|1] "" Vector__XXX
 SG_ KP0_Forced500k : 31|1@1+ (1,0) [0|1] "" Vector__XXX
 SG_ KP0_UptimeSec : 32|16@1+ (1,0) [0|65535] "s" Vector__XXX
 SG_ KP0_NodeId : 48|8@1+ (1,0) [0|7] "" Vector__XXX
 SG_ KP0_Seq : 56|8@1+ (1,0) [0|255] "" Vector__XXX

BO_ 833 KP0_Inputs: 8 RCM
 SG_ KP0_CH01_In : 0|1@1+ (1,0) [0|1] "" Vector__XXX
 SG_ KP0_CH02_In : 1|1@1+ (1,0) [0|1] "" Vector__XXX
 SG_ KP0_CH03_In : 2|1@1+ (1,0) [0|1] "" Vector__XXX
 SG_ KP0_CH04_In : 3|1@1+ (1,0) [0|1] "" Vector__XXX
 SG_ KP0_CH05_In : 4|1@1+ (1,0) [0|1] "" Vector__XXX
 SG_ KP0_CH06_In : 5|1@1+ (1,0) [0|1] "" Vector__XXX
 SG_ KP0_CH07_In : 6|1@1+ (1,0) [0|1] "" Vector__XXX
 SG_ KP0_CH08_In : 7|1@1+ (1,0) [0|1] "" Vector__XXX
 SG_ KP0_CH09_In : 8|1@1+ (1,0) [0|1] "" Vector__XXX
 SG_ KP0_CH10_In : 9|1@1+ (1,0) [0|1] "" Vector__XXX
 SG_ KP0_CH11_In : 10|1@1+ (1,0) [0|1] "" Vector__XXX
 SG_ KP0_CH12_In : 11|1@1+ (1,0) [0|1] "" Vector__XXX
 SG_ KP0_CH13_In : 12|1@1+ (1,0) [0|1] "" Vector__XXX
 SG_ KP0_CH14_In : 13|1@1+ (1,0) [0|1] "" Vector__XXX
 SG_ KP0_CH15_In : 14|1@1+ (1,0) [0|1] "" Vector__XXX
 SG_ KP0_CH16_In : 15|1@1+ (1,0) [0|1] "" Vector__XXX
 SG_ KP0_CH17_In : 16|1@1+ (1,0) [0|1] "" Vector__XXX
 SG_ KP0_CH18_In : 17|1@1+ (1,0) [0|1] "" Vector__XXX
 SG_ KP0_CH19_In : 18|1@1+ (1,0) [0|1] "" Vector__XXX
 SG_ KP0_CH20_In : 19|1@1+ (1,0) [0|1] "" Vector__XXX
 SG_ KP0_CH21_In : 20|1@1+ (1,0) [0|1] "" Vector__XXX
 SG_ KP0_Aux1 : 24|1@1+ (1,0) [0|1] "" Vector__XXX
 SG_ KP0_Aux2 : 25|1@1+ (1,0) [0|1] "" Vector__XXX
 SG_ KP0_Aux3 : 26|1@1+ (1,0) [0|1] "" Vector__XXX
 SG_ KP0_CH01_Sense : 32|1@1+ (1,0) [0|1] "" Vector__XXX
 SG_ KP0_CH02_Sense : 33|1@1+ (1,0) [0|1] "" Vector__XXX
 SG_ KP0_CH03_Sense : 34|1@1+ (1,0) [0|1] "" Vector__XXX
 SG_ KP0_CH04_Sense : 35|1@1+ (1,0) [0|1] "" Vector__XXX
 SG_ KP0_CH05_Sense : 36|1@1+ (1,0) [0|1] "" Vector__XXX
 SG_ KP0_CH06_Sense : 37|1@1+ (1,0) [0|1] "" Vector__XXX
 SG_ KP0_CH07_Sense : 38|1@1+ (1,0) [0|1] "" Vector__XXX
 SG_ KP0_CH08_Sense : 39|1@1+ (1,0) [0|1] "" Vector__XXX
 SG_ KP0_CH09_Sense : 40|1@1+ (1,0) [0|1] "" Vector__XXX
 SG_ KP0_CH10_Sense : 41|1@1+ (1,0) [0|1] "" Vector__XXX
 SG_ KP0_CH11_Sense : 42|1@1+ (1,0) [0|1] "" Vector__XXX
 SG_ KP0_CH12_Sense : 43|1@1+ (1,0) [0|1] "" Vector__XXX
 SG_ KP0_CH13_Sense : 44|1@1+ (1,0) [0|1] "" Vector__XXX
 SG_ KP0_CH14_Sense : 45|1@1+ (1,0) [0|1] "" Vector__XXX
 SG_ KP0_CH15_Sense : 46|1@1+ (1,0) [0|1] "" Vector__XXX
 SG_ KP0_CH16_Sense : 47|1@1+ (1,0) [0|1] "" Vector__XXX
 SG_ KP0_CH17_Sense : 48|1@1+ (1,0) [0|1] "" Vector__XXX
 SG_ KP0_CH18_Sense : 49|1@1+ (1,0) [0|1] "" Vector__XXX
 SG_ KP0_CH19_Sense : 50|1@1+ (1,0) [0|1] "" Vector__XXX
 SG_ KP0_CH20_Sense : 51|1@1+ (1,0) [0|1] "" Vector__XXX
 SG_ KP0_CH21_Sense : 52|1@1+ (1,0) [0|1] "" Vector__XXX
 SG_ KP0_InSeq : 56|8@1+ (1,0) [0|255] "" Vector__XXX

BO_ 834 KP0_Faults: 8 RCM
 SG_ KP0_CH01_Open : 0|1@1+ (1,0) [0|1] "" Vector__XXX
 SG_ KP0_CH02_Open : 1|1@1+ (1,0) [0|1] "" Vector__XXX
 SG_ KP0_CH03_Open : 2|1@1+ (1,0) [0|1] "" Vector__XXX
 SG_ KP0_CH04_Open : 3|1@1+ (1,0) [0|1] "" Vector__XXX
 SG_ KP0_CH05_Open : 4|1@1+ (1,0) [0|1] "" Vector__XXX
 SG_ KP0_CH06_Open : 5|1@1+ (1,0) [0|1] "" Vector__XXX
 SG_ KP0_CH07_Open : 6|1@1+ (1,0) [0|1] "" Vector__XXX
 SG_ KP0_CH08_Open : 7|1@1+ (1,0) [0|1] "" Vector__XXX
 SG_ KP0_CH09_Open : 8|1@1+ (1,0) [0|1] "" Vector__XXX
 SG_ KP0_CH10_Open : 9|1@1+ (1,0) [0|1] "" Vector__XXX
 SG_ KP0_CH11_Open : 10|1@1+ (1,0) [0|1] "" Vector__XXX
 SG_ KP0_CH12_Open : 11|1@1+ (1,0) [0|1] "" Vector__XXX
 SG_ KP0_CH13_Open : 12|1@1+ (1,0) [0|1] "" Vector__XXX
 SG_ KP0_CH14_Open : 13|1@1+ (1,0) [0|1] "" Vector__XXX
 SG_ KP0_CH15_Open : 14|1@1+ (1,0) [0|1] "" Vector__XXX
 SG_ KP0_CH16_Open : 15|1@1+ (1,0) [0|1] "" Vector__XXX
 SG_ KP0_CH17_Open : 16|1@1+ (1,0) [0|1] "" Vector__XXX
 SG_ KP0_CH18_Open : 17|1@1+ (1,0) [0|1] "" Vector__XXX
 SG_ KP0_CH19_Open : 18|1@1+ (1,0) [0|1] "" Vector__XXX
 SG_ KP0_CH20_Open : 19|1@1+ (1,0) [0|1] "" Vector__XXX
 SG_ KP0_CH21_Open : 20|1@1+ (1,0) [0|1] "" Vector__XXX
 SG_ KP0_CH01_Short : 24|1@1+ (1,0) [0|1] "" Vector__XXX
 SG_ KP0_CH02_Short : 25|1@1+ (1,0) [0|1] "" Vector__XXX
 SG_ KP0_CH03_Short : 26|1@1+ (1,0) [0|1] "" Vector__XXX
 SG_ KP0_CH04_Short : 27|1@1+ (1,0) [0|1] "" Vector__XXX
 SG_ KP0_CH05_Short : 28|1@1+ (1,0) [0|1] "" Vector__XXX
 SG_ KP0_CH06_Short : 29|1@1+ (1,0) [0|1] "" Vector__XXX
 SG_ KP0_CH07_Short : 30|1@1+ (1,0) [0|1] "" Vector__XXX
 SG_ KP0_CH08_Short : 31|1@1+ (1,0) [0|1] "" Vector__XXX
 SG_ KP0_CH09_Short : 32|1@1+ (1,0) [0|1] "" Vector__XXX
 SG_ KP0_CH10_Short : 33|1@1+ (1,0) [0|1] "" Vector__XXX
 SG_ KP0_CH11_Short : 34|1@1+ (1,0) [0|1] "" Vector__XXX
 SG_ KP0_CH12_Short : 35|1@1+ (1,0) [0|1] "" Vector__XXX
 SG_ KP0_CH13_Short : 36|1@1+ (1,0) [0|1] "" Vector__XXX
 SG_ KP0_CH14_Short : 37|1@1+ (1,0) [0|1] "" Vector__XXX
 SG_ KP0_CH15_Short : 38|1@1+ (1,0) [0|1] "" Vector__XXX
 SG_ KP0_CH16_Short : 39|1@1+ (1,0) [0|1] "" Vector__XXX
 SG_ KP0_CH17_Short : 40|1@1+ (1,0) [0|1] "" Vector__XXX
 SG_ KP0_CH18_Short : 41|1@1+ (1,0) [0|1] "" Vector__XXX
 SG_ KP0_CH19_Short : 42|1@1+ (1,0) [0|1] "" Vector__XXX
 SG_ KP0_CH20_Short : 43|1@1+ (1,0) [0|1] "" Vector__XXX
 SG_ KP0_CH21_Short : 44|1@1+ (1,0) [0|1] "" Vector__XXX
 SG_ KP0_FaultSeq : 56|8@1+ (1,0) [0|255] "" Vector__XXX

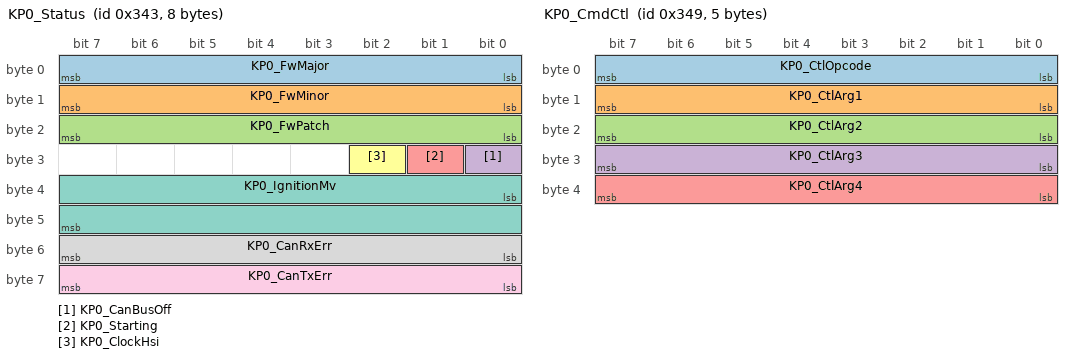
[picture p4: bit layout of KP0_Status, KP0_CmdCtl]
BO_ 835 KP0_Status: 8 RCM
 SG_ KP0_FwMajor : 0|8@1+ (1,0) [0|255] "" Vector__XXX
 SG_ KP0_FwMinor : 8|8@1+ (1,0) [0|255] "" Vector__XXX
 SG_ KP0_FwPatch : 16|8@1+ (1,0) [0|255] "" Vector__XXX
 SG_ KP0_CanBusOff : 24|1@1+ (1,0) [0|1] "" Vector__XXX
 SG_ KP0_Starting : 25|1@1+ (1,0) [0|1] "" Vector__XXX
 SG_ KP0_ClockHsi : 26|1@1+ (1,0) [0|1] "" Vector__XXX
 SG_ KP0_IgnitionMv : 32|16@1+ (1,0) [0|65535] "mV" Vector__XXX
 SG_ KP0_CanRxErr : 48|8@1+ (1,0) [0|255] "" Vector__XXX
 SG_ KP0_CanTxErr : 56|8@1+ (1,0) [0|255] "" Vector__XXX

BO_ 840 KP0_CmdSet: 6 ECU
 SG_ KP0_SetMask01 : 0|1@1+ (1,0) [0|1] "" Vector__XXX
 SG_ KP0_SetMask02 : 1|1@1+ (1,0) [0|1] "" Vector__XXX
 SG_ KP0_SetMask03 : 2|1@1+ (1,0) [0|1] "" Vector__XXX
 SG_ KP0_SetMask04 : 3|1@1+ (1,0) [0|1] "" Vector__XXX
 SG_ KP0_SetMask05 : 4|1@1+ (1,0) [0|1] "" Vector__XXX
 SG_ KP0_SetMask06 : 5|1@1+ (1,0) [0|1] "" Vector__XXX
 SG_ KP0_SetMask07 : 6|1@1+ (1,0) [0|1] "" Vector__XXX
 SG_ KP0_SetMask08 : 7|1@1+ (1,0) [0|1] "" Vector__XXX
 SG_ KP0_SetMask09 : 8|1@1+ (1,0) [0|1] "" Vector__XXX
 SG_ KP0_SetMask10 : 9|1@1+ (1,0) [0|1] "" Vector__XXX
 SG_ KP0_SetMask11 : 10|1@1+ (1,0) [0|1] "" Vector__XXX
 SG_ KP0_SetMask12 : 11|1@1+ (1,0) [0|1] "" Vector__XXX
 SG_ KP0_SetMask13 : 12|1@1+ (1,0) [0|1] "" Vector__XXX
 SG_ KP0_SetMask14 : 13|1@1+ (1,0) [0|1] "" Vector__XXX
 SG_ KP0_SetMask15 : 14|1@1+ (1,0) [0|1] "" Vector__XXX
 SG_ KP0_SetMask16 : 15|1@1+ (1,0) [0|1] "" Vector__XXX
 SG_ KP0_SetMask17 : 16|1@1+ (1,0) [0|1] "" Vector__XXX
 SG_ KP0_SetMask18 : 17|1@1+ (1,0) [0|1] "" Vector__XXX
 SG_ KP0_SetMask19 : 18|1@1+ (1,0) [0|1] "" Vector__XXX
 SG_ KP0_SetMask20 : 19|1@1+ (1,0) [0|1] "" Vector__XXX
 SG_ KP0_SetMask21 : 20|1@1+ (1,0) [0|1] "" Vector__XXX
 SG_ KP0_SetVal01 : 24|1@1+ (1,0) [0|1] "" Vector__XXX
 SG_ KP0_SetVal02 : 25|1@1+ (1,0) [0|1] "" Vector__XXX
 SG_ KP0_SetVal03 : 26|1@1+ (1,0) [0|1] "" Vector__XXX
 SG_ KP0_SetVal04 : 27|1@1+ (1,0) [0|1] "" Vector__XXX
 SG_ KP0_SetVal05 : 28|1@1+ (1,0) [0|1] "" Vector__XXX
 SG_ KP0_SetVal06 : 29|1@1+ (1,0) [0|1] "" Vector__XXX
 SG_ KP0_SetVal07 : 30|1@1+ (1,0) [0|1] "" Vector__XXX
 SG_ KP0_SetVal08 : 31|1@1+ (1,0) [0|1] "" Vector__XXX
 SG_ KP0_SetVal09 : 32|1@1+ (1,0) [0|1] "" Vector__XXX
 SG_ KP0_SetVal10 : 33|1@1+ (1,0) [0|1] "" Vector__XXX
 SG_ KP0_SetVal11 : 34|1@1+ (1,0) [0|1] "" Vector__XXX
 SG_ KP0_SetVal12 : 35|1@1+ (1,0) [0|1] "" Vector__XXX
 SG_ KP0_SetVal13 : 36|1@1+ (1,0) [0|1] "" Vector__XXX
 SG_ KP0_SetVal14 : 37|1@1+ (1,0) [0|1] "" Vector__XXX
 SG_ KP0_SetVal15 : 38|1@1+ (1,0) [0|1] "" Vector__XXX
 SG_ KP0_SetVal16 : 39|1@1+ (1,0) [0|1] "" Vector__XXX
 SG_ KP0_SetVal17 : 40|1@1+ (1,0) [0|1] "" Vector__XXX
 SG_ KP0_SetVal18 : 41|1@1+ (1,0) [0|1] "" Vector__XXX
 SG_ KP0_SetVal19 : 42|1@1+ (1,0) [0|1] "" Vector__XXX
 SG_ KP0_SetVal20 : 43|1@1+ (1,0) [0|1] "" Vector__XXX
 SG_ KP0_SetVal21 : 44|1@1+ (1,0) [0|1] "" Vector__XXX

BO_ 841 KP0_CmdCtl: 5 ECU
 SG_ KP0_CtlOpcode : 0|8@1+ (1,0) [0|255] "" Vector__XXX
 SG_ KP0_CtlArg1 : 8|8@1+ (1,0) [0|255] "" Vector__XXX
 SG_ KP0_CtlArg2 : 16|8@1+ (1,0) [0|255] "" Vector__XXX
 SG_ KP0_CtlArg3 : 24|8@1+ (1,0) [0|255] "" Vector__XXX
 SG_ KP0_CtlArg4 : 32|8@1+ (1,0) [0|255] "" Vector__XXX

BO_ 848 KP1_Outputs: 8 RCM
 SG_ KP1_CH01_Out : 0|1@1+ (1,0) [0|1] "" Vector__XXX
 SG_ KP1_CH02_Out : 1|1@1+ (1,0) [0|1] "" Vector__XXX
 SG_ KP1_CH03_Out : 2|1@1+ (1,0) [0|1] "" Vector__XXX
 SG_ KP1_CH04_Out : 3|1@1+ (1,0) [0|1] "" Vector__XXX
 SG_ KP1_CH05_Out : 4|1@1+ (1,0) [0|1] "" Vector__XXX
 SG_ KP1_CH06_Out : 5|1@1+ (1,0) [0|1] "" Vector__XXX
 SG_ KP1_CH07_Out : 6|1@1+ (1,0) [0|1] "" Vector__XXX
 SG_ KP1_CH08_Out : 7|1@1+ (1,0) [0|1] "" Vector__XXX
 SG_ KP1_CH09_Out : 8|1@1+ (1,0) [0|1] "" Vector__XXX
 SG_ KP1_CH10_Out : 9|1@1+ (1,0) [0|1] "" Vector__XXX
 SG_ KP1_CH11_Out : 10|1@1+ (1,0) [0|1] "" Vector__XXX
 SG_ KP1_CH12_Out : 11|1@1+ (1,0) [0|1] "" Vector__XXX
 SG_ KP1_CH13_Out : 12|1@1+ (1,0) [0|1] "" Vector__XXX
 SG_ KP1_CH14_Out : 13|1@1+ (1,0) [0|1] "" Vector__XXX
 SG_ KP1_CH15_Out : 14|1@1+ (1,0) [0|1] "" Vector__XXX
 SG_ KP1_CH16_Out : 15|1@1+ (1,0) [0|1] "" Vector__XXX
 SG_ KP1_CH17_Out : 16|1@1+ (1,0) [0|1] "" Vector__XXX
 SG_ KP1_CH18_Out : 17|1@1+ (1,0) [0|1] "" Vector__XXX
 SG_ KP1_CH19_Out : 18|1@1+ (1,0) [0|1] "" Vector__XXX
 SG_ KP1_CH20_Out : 19|1@1+ (1,0) [0|1] "" Vector__XXX
 SG_ KP1_CH21_Out : 20|1@1+ (1,0) [0|1] "" Vector__XXX
 SG_ KP1_OutputsEnabled : 24|1@1+ (1,0) [0|1] "" Vector__XXX
 SG_ KP1_Failsafe : 25|1@1+ (1,0) [0|1] "" Vector__XXX
 SG_ KP1_AnyFault : 26|1@1+ (1,0) [0|1] "" Vector__XXX
 SG_ KP1_ImuOk : 27|1@1+ (1,0) [0|1] "" Vector__XXX
 SG_ KP1_EepromOk : 28|1@1+ (1,0) [0|1] "" Vector__XXX
 SG_ KP1_RoleKeypad : 29|1@1+ (1,0) [0|1] "" Vector__XXX
 SG_ KP1_IgnitionOn : 30|1@1+ (1,0) [0|1] "" Vector__XXX
 SG_ KP1_Forced500k : 31|1@1+ (1,0) [0|1] "" Vector__XXX
 SG_ KP1_UptimeSec : 32|16@1+ (1,0) [0|65535] "s" Vector__XXX
 SG_ KP1_NodeId : 48|8@1+ (1,0) [0|7] "" Vector__XXX
 SG_ KP1_Seq : 56|8@1+ (1,0) [0|255] "" Vector__XXX

BO_ 849 KP1_Inputs: 8 RCM
 SG_ KP1_CH01_In : 0|1@1+ (1,0) [0|1] "" Vector__XXX
 SG_ KP1_CH02_In : 1|1@1+ (1,0) [0|1] "" Vector__XXX
 SG_ KP1_CH03_In : 2|1@1+ (1,0) [0|1] "" Vector__XXX
 SG_ KP1_CH04_In : 3|1@1+ (1,0) [0|1] "" Vector__XXX
 SG_ KP1_CH05_In : 4|1@1+ (1,0) [0|1] "" Vector__XXX
 SG_ KP1_CH06_In : 5|1@1+ (1,0) [0|1] "" Vector__XXX
 SG_ KP1_CH07_In : 6|1@1+ (1,0) [0|1] "" Vector__XXX
 SG_ KP1_CH08_In : 7|1@1+ (1,0) [0|1] "" Vector__XXX
 SG_ KP1_CH09_In : 8|1@1+ (1,0) [0|1] "" Vector__XXX
 SG_ KP1_CH10_In : 9|1@1+ (1,0) [0|1] "" Vector__XXX
 SG_ KP1_CH11_In : 10|1@1+ (1,0) [0|1] "" Vector__XXX
 SG_ KP1_CH12_In : 11|1@1+ (1,0) [0|1] "" Vector__XXX
 SG_ KP1_CH13_In : 12|1@1+ (1,0) [0|1] "" Vector__XXX
 SG_ KP1_CH14_In : 13|1@1+ (1,0) [0|1] "" Vector__XXX
 SG_ KP1_CH15_In : 14|1@1+ (1,0) [0|1] "" Vector__XXX
 SG_ KP1_CH16_In : 15|1@1+ (1,0) [0|1] "" Vector__XXX
 SG_ KP1_CH17_In : 16|1@1+ (1,0) [0|1] "" Vector__XXX
 SG_ KP1_CH18_In : 17|1@1+ (1,0) [0|1] "" Vector__XXX
 SG_ KP1_CH19_In : 18|1@1+ (1,0) [0|1] "" Vector__XXX
 SG_ KP1_CH20_In : 19|1@1+ (1,0) [0|1] "" Vector__XXX
 SG_ KP1_CH21_In : 20|1@1+ (1,0) [0|1] "" Vector__XXX
 SG_ KP1_Aux1 : 24|1@1+ (1,0) [0|1] "" Vector__XXX
 SG_ KP1_Aux2 : 25|1@1+ (1,0) [0|1] "" Vector__XXX
 SG_ KP1_Aux3 : 26|1@1+ (1,0) [0|1] "" Vector__XXX
 SG_ KP1_CH01_Sense : 32|1@1+ (1,0) [0|1] "" Vector__XXX
 SG_ KP1_CH02_Sense : 33|1@1+ (1,0) [0|1] "" Vector__XXX
 SG_ KP1_CH03_Sense : 34|1@1+ (1,0) [0|1] "" Vector__XXX
 SG_ KP1_CH04_Sense : 35|1@1+ (1,0) [0|1] "" Vector__XXX
 SG_ KP1_CH05_Sense : 36|1@1+ (1,0) [0|1] "" Vector__XXX
 SG_ KP1_CH06_Sense : 37|1@1+ (1,0) [0|1] "" Vector__XXX
 SG_ KP1_CH07_Sense : 38|1@1+ (1,0) [0|1] "" Vector__XXX
 SG_ KP1_CH08_Sense : 39|1@1+ (1,0) [0|1] "" Vector__XXX
 SG_ KP1_CH09_Sense : 40|1@1+ (1,0) [0|1] "" Vector__XXX
 SG_ KP1_CH10_Sense : 41|1@1+ (1,0) [0|1] "" Vector__XXX
 SG_ KP1_CH11_Sense : 42|1@1+ (1,0) [0|1] "" Vector__XXX
 SG_ KP1_CH12_Sense : 43|1@1+ (1,0) [0|1] "" Vector__XXX
 SG_ KP1_CH13_Sense : 44|1@1+ (1,0) [0|1] "" Vector__XXX
 SG_ KP1_CH14_Sense : 45|1@1+ (1,0) [0|1] "" Vector__XXX
 SG_ KP1_CH15_Sense : 46|1@1+ (1,0) [0|1] "" Vector__XXX
 SG_ KP1_CH16_Sense : 47|1@1+ (1,0) [0|1] "" Vector__XXX
 SG_ KP1_CH17_Sense : 48|1@1+ (1,0) [0|1] "" Vector__XXX
 SG_ KP1_CH18_Sense : 49|1@1+ (1,0) [0|1] "" Vector__XXX
 SG_ KP1_CH19_Sense : 50|1@1+ (1,0) [0|1] "" Vector__XXX
 SG_ KP1_CH20_Sense : 51|1@1+ (1,0) [0|1] "" Vector__XXX
 SG_ KP1_CH21_Sense : 52|1@1+ (1,0) [0|1] "" Vector__XXX
 SG_ KP1_InSeq : 56|8@1+ (1,0) [0|255] "" Vector__XXX

BO_ 850 KP1_Faults: 8 RCM
 SG_ KP1_CH01_Open : 0|1@1+ (1,0) [0|1] "" Vector__XXX
 SG_ KP1_CH02_Open : 1|1@1+ (1,0) [0|1] "" Vector__XXX
 SG_ KP1_CH03_Open : 2|1@1+ (1,0) [0|1] "" Vector__XXX
 SG_ KP1_CH04_Open : 3|1@1+ (1,0) [0|1] "" Vector__XXX
 SG_ KP1_CH05_Open : 4|1@1+ (1,0) [0|1] "" Vector__XXX
 SG_ KP1_CH06_Open : 5|1@1+ (1,0) [0|1] "" Vector__XXX
 SG_ KP1_CH07_Open : 6|1@1+ (1,0) [0|1] "" Vector__XXX
 SG_ KP1_CH08_Open : 7|1@1+ (1,0) [0|1] "" Vector__XXX
 SG_ KP1_CH09_Open : 8|1@1+ (1,0) [0|1] "" Vector__XXX
 SG_ KP1_CH10_Open : 9|1@1+ (1,0) [0|1] "" Vector__XXX
 SG_ KP1_CH11_Open : 10|1@1+ (1,0) [0|1] "" Vector__XXX
 SG_ KP1_CH12_Open : 11|1@1+ (1,0) [0|1] "" Vector__XXX
 SG_ KP1_CH13_Open : 12|1@1+ (1,0) [0|1] "" Vector__XXX
 SG_ KP1_CH14_Open : 13|1@1+ (1,0) [0|1] "" Vector__XXX
 SG_ KP1_CH15_Open : 14|1@1+ (1,0) [0|1] "" Vector__XXX
 SG_ KP1_CH16_Open : 15|1@1+ (1,0) [0|1] "" Vector__XXX
 SG_ KP1_CH17_Open : 16|1@1+ (1,0) [0|1] "" Vector__XXX
 SG_ KP1_CH18_Open : 17|1@1+ (1,0) [0|1] "" Vector__XXX
 SG_ KP1_CH19_Open : 18|1@1+ (1,0) [0|1] "" Vector__XXX
 SG_ KP1_CH20_Open : 19|1@1+ (1,0) [0|1] "" Vector__XXX
 SG_ KP1_CH21_Open : 20|1@1+ (1,0) [0|1] "" Vector__XXX
 SG_ KP1_CH01_Short : 24|1@1+ (1,0) [0|1] "" Vector__XXX
 SG_ KP1_CH02_Short : 25|1@1+ (1,0) [0|1] "" Vector__XXX
 SG_ KP1_CH03_Short : 26|1@1+ (1,0) [0|1] "" Vector__XXX
 SG_ KP1_CH04_Short : 27|1@1+ (1,0) [0|1] "" Vector__XXX
 SG_ KP1_CH05_Short : 28|1@1+ (1,0) [0|1] "" Vector__XXX
 SG_ KP1_CH06_Short : 29|1@1+ (1,0) [0|1] "" Vector__XXX
 SG_ KP1_CH07_Short : 30|1@1+ (1,0) [0|1] "" Vector__XXX
 SG_ KP1_CH08_Short : 31|1@1+ (1,0) [0|1] "" Vector__XXX
 SG_ KP1_CH09_Short : 32|1@1+ (1,0) [0|1] "" Vector__XXX
 SG_ KP1_CH10_Short : 33|1@1+ (1,0) [0|1] "" Vector__XXX
 SG_ KP1_CH11_Short : 34|1@1+ (1,0) [0|1] "" Vector__XXX
 SG_ KP1_CH12_Short : 35|1@1+ (1,0) [0|1] "" Vector__XXX
 SG_ KP1_CH13_Short : 36|1@1+ (1,0) [0|1] "" Vector__XXX
 SG_ KP1_CH14_Short : 37|1@1+ (1,0) [0|1] "" Vector__XXX
 SG_ KP1_CH15_Short : 38|1@1+ (1,0) [0|1] "" Vector__XXX
 SG_ KP1_CH16_Short : 39|1@1+ (1,0) [0|1] "" Vector__XXX
 SG_ KP1_CH17_Short : 40|1@1+ (1,0) [0|1] "" Vector__XXX
 SG_ KP1_CH18_Short : 41|1@1+ (1,0) [0|1] "" Vector__XXX
 SG_ KP1_CH19_Short : 42|1@1+ (1,0) [0|1] "" Vector__XXX
 SG_ KP1_CH20_Short : 43|1@1+ (1,0) [0|1] "" Vector__XXX
 SG_ KP1_CH21_Short : 44|1@1+ (1,0) [0|1] "" Vector__XXX
 SG_ KP1_FaultSeq : 56|8@1+ (1,0) [0|255] "" Vector__XXX

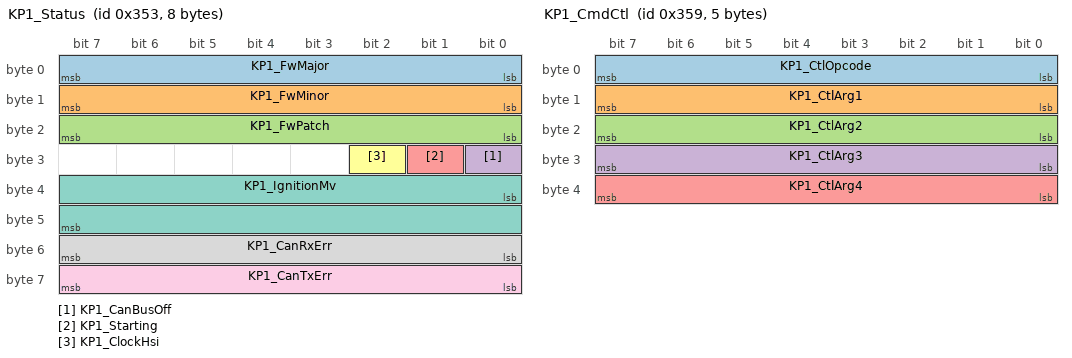
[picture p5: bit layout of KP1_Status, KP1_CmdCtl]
BO_ 851 KP1_Status: 8 RCM
 SG_ KP1_FwMajor : 0|8@1+ (1,0) [0|255] "" Vector__XXX
 SG_ KP1_FwMinor : 8|8@1+ (1,0) [0|255] "" Vector__XXX
 SG_ KP1_FwPatch : 16|8@1+ (1,0) [0|255] "" Vector__XXX
 SG_ KP1_CanBusOff : 24|1@1+ (1,0) [0|1] "" Vector__XXX
 SG_ KP1_Starting : 25|1@1+ (1,0) [0|1] "" Vector__XXX
 SG_ KP1_ClockHsi : 26|1@1+ (1,0) [0|1] "" Vector__XXX
 SG_ KP1_IgnitionMv : 32|16@1+ (1,0) [0|65535] "mV" Vector__XXX
 SG_ KP1_CanRxErr : 48|8@1+ (1,0) [0|255] "" Vector__XXX
 SG_ KP1_CanTxErr : 56|8@1+ (1,0) [0|255] "" Vector__XXX

BO_ 856 KP1_CmdSet: 6 ECU
 SG_ KP1_SetMask01 : 0|1@1+ (1,0) [0|1] "" Vector__XXX
 SG_ KP1_SetMask02 : 1|1@1+ (1,0) [0|1] "" Vector__XXX
 SG_ KP1_SetMask03 : 2|1@1+ (1,0) [0|1] "" Vector__XXX
 SG_ KP1_SetMask04 : 3|1@1+ (1,0) [0|1] "" Vector__XXX
 SG_ KP1_SetMask05 : 4|1@1+ (1,0) [0|1] "" Vector__XXX
 SG_ KP1_SetMask06 : 5|1@1+ (1,0) [0|1] "" Vector__XXX
 SG_ KP1_SetMask07 : 6|1@1+ (1,0) [0|1] "" Vector__XXX
 SG_ KP1_SetMask08 : 7|1@1+ (1,0) [0|1] "" Vector__XXX
 SG_ KP1_SetMask09 : 8|1@1+ (1,0) [0|1] "" Vector__XXX
 SG_ KP1_SetMask10 : 9|1@1+ (1,0) [0|1] "" Vector__XXX
 SG_ KP1_SetMask11 : 10|1@1+ (1,0) [0|1] "" Vector__XXX
 SG_ KP1_SetMask12 : 11|1@1+ (1,0) [0|1] "" Vector__XXX
 SG_ KP1_SetMask13 : 12|1@1+ (1,0) [0|1] "" Vector__XXX
 SG_ KP1_SetMask14 : 13|1@1+ (1,0) [0|1] "" Vector__XXX
 SG_ KP1_SetMask15 : 14|1@1+ (1,0) [0|1] "" Vector__XXX
 SG_ KP1_SetMask16 : 15|1@1+ (1,0) [0|1] "" Vector__XXX
 SG_ KP1_SetMask17 : 16|1@1+ (1,0) [0|1] "" Vector__XXX
 SG_ KP1_SetMask18 : 17|1@1+ (1,0) [0|1] "" Vector__XXX
 SG_ KP1_SetMask19 : 18|1@1+ (1,0) [0|1] "" Vector__XXX
 SG_ KP1_SetMask20 : 19|1@1+ (1,0) [0|1] "" Vector__XXX
 SG_ KP1_SetMask21 : 20|1@1+ (1,0) [0|1] "" Vector__XXX
 SG_ KP1_SetVal01 : 24|1@1+ (1,0) [0|1] "" Vector__XXX
 SG_ KP1_SetVal02 : 25|1@1+ (1,0) [0|1] "" Vector__XXX
 SG_ KP1_SetVal03 : 26|1@1+ (1,0) [0|1] "" Vector__XXX
 SG_ KP1_SetVal04 : 27|1@1+ (1,0) [0|1] "" Vector__XXX
 SG_ KP1_SetVal05 : 28|1@1+ (1,0) [0|1] "" Vector__XXX
 SG_ KP1_SetVal06 : 29|1@1+ (1,0) [0|1] "" Vector__XXX
 SG_ KP1_SetVal07 : 30|1@1+ (1,0) [0|1] "" Vector__XXX
 SG_ KP1_SetVal08 : 31|1@1+ (1,0) [0|1] "" Vector__XXX
 SG_ KP1_SetVal09 : 32|1@1+ (1,0) [0|1] "" Vector__XXX
 SG_ KP1_SetVal10 : 33|1@1+ (1,0) [0|1] "" Vector__XXX
 SG_ KP1_SetVal11 : 34|1@1+ (1,0) [0|1] "" Vector__XXX
 SG_ KP1_SetVal12 : 35|1@1+ (1,0) [0|1] "" Vector__XXX
 SG_ KP1_SetVal13 : 36|1@1+ (1,0) [0|1] "" Vector__XXX
 SG_ KP1_SetVal14 : 37|1@1+ (1,0) [0|1] "" Vector__XXX
 SG_ KP1_SetVal15 : 38|1@1+ (1,0) [0|1] "" Vector__XXX
 SG_ KP1_SetVal16 : 39|1@1+ (1,0) [0|1] "" Vector__XXX
 SG_ KP1_SetVal17 : 40|1@1+ (1,0) [0|1] "" Vector__XXX
 SG_ KP1_SetVal18 : 41|1@1+ (1,0) [0|1] "" Vector__XXX
 SG_ KP1_SetVal19 : 42|1@1+ (1,0) [0|1] "" Vector__XXX
 SG_ KP1_SetVal20 : 43|1@1+ (1,0) [0|1] "" Vector__XXX
 SG_ KP1_SetVal21 : 44|1@1+ (1,0) [0|1] "" Vector__XXX

BO_ 857 KP1_CmdCtl: 5 ECU
 SG_ KP1_CtlOpcode : 0|8@1+ (1,0) [0|255] "" Vector__XXX
 SG_ KP1_CtlArg1 : 8|8@1+ (1,0) [0|255] "" Vector__XXX
 SG_ KP1_CtlArg2 : 16|8@1+ (1,0) [0|255] "" Vector__XXX
 SG_ KP1_CtlArg3 : 24|8@1+ (1,0) [0|255] "" Vector__XXX
 SG_ KP1_CtlArg4 : 32|8@1+ (1,0) [0|255] "" Vector__XXX

BO_ 864 KP2_Outputs: 8 RCM
 SG_ KP2_CH01_Out : 0|1@1+ (1,0) [0|1] "" Vector__XXX
 SG_ KP2_CH02_Out : 1|1@1+ (1,0) [0|1] "" Vector__XXX
 SG_ KP2_CH03_Out : 2|1@1+ (1,0) [0|1] "" Vector__XXX
 SG_ KP2_CH04_Out : 3|1@1+ (1,0) [0|1] "" Vector__XXX
 SG_ KP2_CH05_Out : 4|1@1+ (1,0) [0|1] "" Vector__XXX
 SG_ KP2_CH06_Out : 5|1@1+ (1,0) [0|1] "" Vector__XXX
 SG_ KP2_CH07_Out : 6|1@1+ (1,0) [0|1] "" Vector__XXX
 SG_ KP2_CH08_Out : 7|1@1+ (1,0) [0|1] "" Vector__XXX
 SG_ KP2_CH09_Out : 8|1@1+ (1,0) [0|1] "" Vector__XXX
 SG_ KP2_CH10_Out : 9|1@1+ (1,0) [0|1] "" Vector__XXX
 SG_ KP2_CH11_Out : 10|1@1+ (1,0) [0|1] "" Vector__XXX
 SG_ KP2_CH12_Out : 11|1@1+ (1,0) [0|1] "" Vector__XXX
 SG_ KP2_CH13_Out : 12|1@1+ (1,0) [0|1] "" Vector__XXX
 SG_ KP2_CH14_Out : 13|1@1+ (1,0) [0|1] "" Vector__XXX
 SG_ KP2_CH15_Out : 14|1@1+ (1,0) [0|1] "" Vector__XXX
 SG_ KP2_CH16_Out : 15|1@1+ (1,0) [0|1] "" Vector__XXX
 SG_ KP2_CH17_Out : 16|1@1+ (1,0) [0|1] "" Vector__XXX
 SG_ KP2_CH18_Out : 17|1@1+ (1,0) [0|1] "" Vector__XXX
 SG_ KP2_CH19_Out : 18|1@1+ (1,0) [0|1] "" Vector__XXX
 SG_ KP2_CH20_Out : 19|1@1+ (1,0) [0|1] "" Vector__XXX
 SG_ KP2_CH21_Out : 20|1@1+ (1,0) [0|1] "" Vector__XXX
 SG_ KP2_OutputsEnabled : 24|1@1+ (1,0) [0|1] "" Vector__XXX
 SG_ KP2_Failsafe : 25|1@1+ (1,0) [0|1] "" Vector__XXX
 SG_ KP2_AnyFault : 26|1@1+ (1,0) [0|1] "" Vector__XXX
 SG_ KP2_ImuOk : 27|1@1+ (1,0) [0|1] "" Vector__XXX
 SG_ KP2_EepromOk : 28|1@1+ (1,0) [0|1] "" Vector__XXX
 SG_ KP2_RoleKeypad : 29|1@1+ (1,0) [0|1] "" Vector__XXX
 SG_ KP2_IgnitionOn : 30|1@1+ (1,0) [0|1] "" Vector__XXX
 SG_ KP2_Forced500k : 31|1@1+ (1,0) [0|1] "" Vector__XXX
 SG_ KP2_UptimeSec : 32|16@1+ (1,0) [0|65535] "s" Vector__XXX
 SG_ KP2_NodeId : 48|8@1+ (1,0) [0|7] "" Vector__XXX
 SG_ KP2_Seq : 56|8@1+ (1,0) [0|255] "" Vector__XXX

BO_ 865 KP2_Inputs: 8 RCM
 SG_ KP2_CH01_In : 0|1@1+ (1,0) [0|1] "" Vector__XXX
 SG_ KP2_CH02_In : 1|1@1+ (1,0) [0|1] "" Vector__XXX
 SG_ KP2_CH03_In : 2|1@1+ (1,0) [0|1] "" Vector__XXX
 SG_ KP2_CH04_In : 3|1@1+ (1,0) [0|1] "" Vector__XXX
 SG_ KP2_CH05_In : 4|1@1+ (1,0) [0|1] "" Vector__XXX
 SG_ KP2_CH06_In : 5|1@1+ (1,0) [0|1] "" Vector__XXX
 SG_ KP2_CH07_In : 6|1@1+ (1,0) [0|1] "" Vector__XXX
 SG_ KP2_CH08_In : 7|1@1+ (1,0) [0|1] "" Vector__XXX
 SG_ KP2_CH09_In : 8|1@1+ (1,0) [0|1] "" Vector__XXX
 SG_ KP2_CH10_In : 9|1@1+ (1,0) [0|1] "" Vector__XXX
 SG_ KP2_CH11_In : 10|1@1+ (1,0) [0|1] "" Vector__XXX
 SG_ KP2_CH12_In : 11|1@1+ (1,0) [0|1] "" Vector__XXX
 SG_ KP2_CH13_In : 12|1@1+ (1,0) [0|1] "" Vector__XXX
 SG_ KP2_CH14_In : 13|1@1+ (1,0) [0|1] "" Vector__XXX
 SG_ KP2_CH15_In : 14|1@1+ (1,0) [0|1] "" Vector__XXX
 SG_ KP2_CH16_In : 15|1@1+ (1,0) [0|1] "" Vector__XXX
 SG_ KP2_CH17_In : 16|1@1+ (1,0) [0|1] "" Vector__XXX
 SG_ KP2_CH18_In : 17|1@1+ (1,0) [0|1] "" Vector__XXX
 SG_ KP2_CH19_In : 18|1@1+ (1,0) [0|1] "" Vector__XXX
 SG_ KP2_CH20_In : 19|1@1+ (1,0) [0|1] "" Vector__XXX
 SG_ KP2_CH21_In : 20|1@1+ (1,0) [0|1] "" Vector__XXX
 SG_ KP2_Aux1 : 24|1@1+ (1,0) [0|1] "" Vector__XXX
 SG_ KP2_Aux2 : 25|1@1+ (1,0) [0|1] "" Vector__XXX
 SG_ KP2_Aux3 : 26|1@1+ (1,0) [0|1] "" Vector__XXX
 SG_ KP2_CH01_Sense : 32|1@1+ (1,0) [0|1] "" Vector__XXX
 SG_ KP2_CH02_Sense : 33|1@1+ (1,0) [0|1] "" Vector__XXX
 SG_ KP2_CH03_Sense : 34|1@1+ (1,0) [0|1] "" Vector__XXX
 SG_ KP2_CH04_Sense : 35|1@1+ (1,0) [0|1] "" Vector__XXX
 SG_ KP2_CH05_Sense : 36|1@1+ (1,0) [0|1] "" Vector__XXX
 SG_ KP2_CH06_Sense : 37|1@1+ (1,0) [0|1] "" Vector__XXX
 SG_ KP2_CH07_Sense : 38|1@1+ (1,0) [0|1] "" Vector__XXX
 SG_ KP2_CH08_Sense : 39|1@1+ (1,0) [0|1] "" Vector__XXX
 SG_ KP2_CH09_Sense : 40|1@1+ (1,0) [0|1] "" Vector__XXX
 SG_ KP2_CH10_Sense : 41|1@1+ (1,0) [0|1] "" Vector__XXX
 SG_ KP2_CH11_Sense : 42|1@1+ (1,0) [0|1] "" Vector__XXX
 SG_ KP2_CH12_Sense : 43|1@1+ (1,0) [0|1] "" Vector__XXX
 SG_ KP2_CH13_Sense : 44|1@1+ (1,0) [0|1] "" Vector__XXX
 SG_ KP2_CH14_Sense : 45|1@1+ (1,0) [0|1] "" Vector__XXX
 SG_ KP2_CH15_Sense : 46|1@1+ (1,0) [0|1] "" Vector__XXX
 SG_ KP2_CH16_Sense : 47|1@1+ (1,0) [0|1] "" Vector__XXX
 SG_ KP2_CH17_Sense : 48|1@1+ (1,0) [0|1] "" Vector__XXX
 SG_ KP2_CH18_Sense : 49|1@1+ (1,0) [0|1] "" Vector__XXX
 SG_ KP2_CH19_Sense : 50|1@1+ (1,0) [0|1] "" Vector__XXX
 SG_ KP2_CH20_Sense : 51|1@1+ (1,0) [0|1] "" Vector__XXX
 SG_ KP2_CH21_Sense : 52|1@1+ (1,0) [0|1] "" Vector__XXX
 SG_ KP2_InSeq : 56|8@1+ (1,0) [0|255] "" Vector__XXX

BO_ 866 KP2_Faults: 8 RCM
 SG_ KP2_CH01_Open : 0|1@1+ (1,0) [0|1] "" Vector__XXX
 SG_ KP2_CH02_Open : 1|1@1+ (1,0) [0|1] "" Vector__XXX
 SG_ KP2_CH03_Open : 2|1@1+ (1,0) [0|1] "" Vector__XXX
 SG_ KP2_CH04_Open : 3|1@1+ (1,0) [0|1] "" Vector__XXX
 SG_ KP2_CH05_Open : 4|1@1+ (1,0) [0|1] "" Vector__XXX
 SG_ KP2_CH06_Open : 5|1@1+ (1,0) [0|1] "" Vector__XXX
 SG_ KP2_CH07_Open : 6|1@1+ (1,0) [0|1] "" Vector__XXX
 SG_ KP2_CH08_Open : 7|1@1+ (1,0) [0|1] "" Vector__XXX
 SG_ KP2_CH09_Open : 8|1@1+ (1,0) [0|1] "" Vector__XXX
 SG_ KP2_CH10_Open : 9|1@1+ (1,0) [0|1] "" Vector__XXX
 SG_ KP2_CH11_Open : 10|1@1+ (1,0) [0|1] "" Vector__XXX
 SG_ KP2_CH12_Open : 11|1@1+ (1,0) [0|1] "" Vector__XXX
 SG_ KP2_CH13_Open : 12|1@1+ (1,0) [0|1] "" Vector__XXX
 SG_ KP2_CH14_Open : 13|1@1+ (1,0) [0|1] "" Vector__XXX
 SG_ KP2_CH15_Open : 14|1@1+ (1,0) [0|1] "" Vector__XXX
 SG_ KP2_CH16_Open : 15|1@1+ (1,0) [0|1] "" Vector__XXX
 SG_ KP2_CH17_Open : 16|1@1+ (1,0) [0|1] "" Vector__XXX
 SG_ KP2_CH18_Open : 17|1@1+ (1,0) [0|1] "" Vector__XXX
 SG_ KP2_CH19_Open : 18|1@1+ (1,0) [0|1] "" Vector__XXX
 SG_ KP2_CH20_Open : 19|1@1+ (1,0) [0|1] "" Vector__XXX
 SG_ KP2_CH21_Open : 20|1@1+ (1,0) [0|1] "" Vector__XXX
 SG_ KP2_CH01_Short : 24|1@1+ (1,0) [0|1] "" Vector__XXX
 SG_ KP2_CH02_Short : 25|1@1+ (1,0) [0|1] "" Vector__XXX
 SG_ KP2_CH03_Short : 26|1@1+ (1,0) [0|1] "" Vector__XXX
 SG_ KP2_CH04_Short : 27|1@1+ (1,0) [0|1] "" Vector__XXX
 SG_ KP2_CH05_Short : 28|1@1+ (1,0) [0|1] "" Vector__XXX
 SG_ KP2_CH06_Short : 29|1@1+ (1,0) [0|1] "" Vector__XXX
 SG_ KP2_CH07_Short : 30|1@1+ (1,0) [0|1] "" Vector__XXX
 SG_ KP2_CH08_Short : 31|1@1+ (1,0) [0|1] "" Vector__XXX
 SG_ KP2_CH09_Short : 32|1@1+ (1,0) [0|1] "" Vector__XXX
 SG_ KP2_CH10_Short : 33|1@1+ (1,0) [0|1] "" Vector__XXX
 SG_ KP2_CH11_Short : 34|1@1+ (1,0) [0|1] "" Vector__XXX
 SG_ KP2_CH12_Short : 35|1@1+ (1,0) [0|1] "" Vector__XXX
 SG_ KP2_CH13_Short : 36|1@1+ (1,0) [0|1] "" Vector__XXX
 SG_ KP2_CH14_Short : 37|1@1+ (1,0) [0|1] "" Vector__XXX
 SG_ KP2_CH15_Short : 38|1@1+ (1,0) [0|1] "" Vector__XXX
 SG_ KP2_CH16_Short : 39|1@1+ (1,0) [0|1] "" Vector__XXX
 SG_ KP2_CH17_Short : 40|1@1+ (1,0) [0|1] "" Vector__XXX
 SG_ KP2_CH18_Short : 41|1@1+ (1,0) [0|1] "" Vector__XXX
 SG_ KP2_CH19_Short : 42|1@1+ (1,0) [0|1] "" Vector__XXX
 SG_ KP2_CH20_Short : 43|1@1+ (1,0) [0|1] "" Vector__XXX
 SG_ KP2_CH21_Short : 44|1@1+ (1,0) [0|1] "" Vector__XXX
 SG_ KP2_FaultSeq : 56|8@1+ (1,0) [0|255] "" Vector__XXX

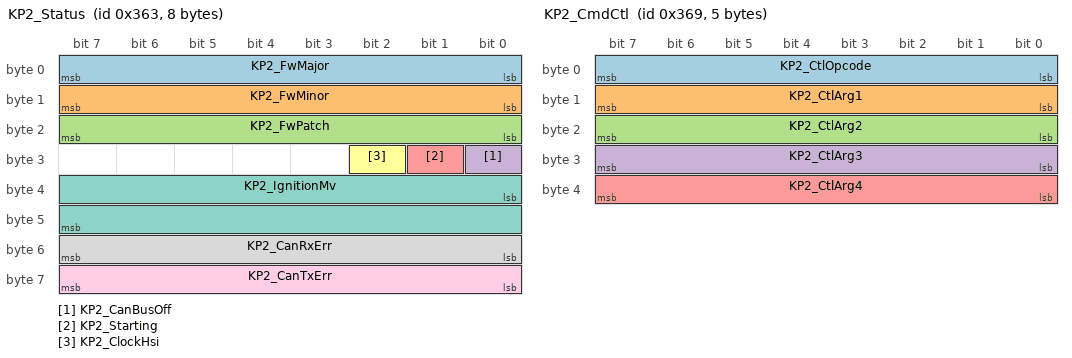
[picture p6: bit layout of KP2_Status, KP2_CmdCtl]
BO_ 867 KP2_Status: 8 RCM
 SG_ KP2_FwMajor : 0|8@1+ (1,0) [0|255] "" Vector__XXX
 SG_ KP2_FwMinor : 8|8@1+ (1,0) [0|255] "" Vector__XXX
 SG_ KP2_FwPatch : 16|8@1+ (1,0) [0|255] "" Vector__XXX
 SG_ KP2_CanBusOff : 24|1@1+ (1,0) [0|1] "" Vector__XXX
 SG_ KP2_Starting : 25|1@1+ (1,0) [0|1] "" Vector__XXX
 SG_ KP2_ClockHsi : 26|1@1+ (1,0) [0|1] "" Vector__XXX
 SG_ KP2_IgnitionMv : 32|16@1+ (1,0) [0|65535] "mV" Vector__XXX
 SG_ KP2_CanRxErr : 48|8@1+ (1,0) [0|255] "" Vector__XXX
 SG_ KP2_CanTxErr : 56|8@1+ (1,0) [0|255] "" Vector__XXX

BO_ 872 KP2_CmdSet: 6 ECU
 SG_ KP2_SetMask01 : 0|1@1+ (1,0) [0|1] "" Vector__XXX
 SG_ KP2_SetMask02 : 1|1@1+ (1,0) [0|1] "" Vector__XXX
 SG_ KP2_SetMask03 : 2|1@1+ (1,0) [0|1] "" Vector__XXX
 SG_ KP2_SetMask04 : 3|1@1+ (1,0) [0|1] "" Vector__XXX
 SG_ KP2_SetMask05 : 4|1@1+ (1,0) [0|1] "" Vector__XXX
 SG_ KP2_SetMask06 : 5|1@1+ (1,0) [0|1] "" Vector__XXX
 SG_ KP2_SetMask07 : 6|1@1+ (1,0) [0|1] "" Vector__XXX
 SG_ KP2_SetMask08 : 7|1@1+ (1,0) [0|1] "" Vector__XXX
 SG_ KP2_SetMask09 : 8|1@1+ (1,0) [0|1] "" Vector__XXX
 SG_ KP2_SetMask10 : 9|1@1+ (1,0) [0|1] "" Vector__XXX
 SG_ KP2_SetMask11 : 10|1@1+ (1,0) [0|1] "" Vector__XXX
 SG_ KP2_SetMask12 : 11|1@1+ (1,0) [0|1] "" Vector__XXX
 SG_ KP2_SetMask13 : 12|1@1+ (1,0) [0|1] "" Vector__XXX
 SG_ KP2_SetMask14 : 13|1@1+ (1,0) [0|1] "" Vector__XXX
 SG_ KP2_SetMask15 : 14|1@1+ (1,0) [0|1] "" Vector__XXX
 SG_ KP2_SetMask16 : 15|1@1+ (1,0) [0|1] "" Vector__XXX
 SG_ KP2_SetMask17 : 16|1@1+ (1,0) [0|1] "" Vector__XXX
 SG_ KP2_SetMask18 : 17|1@1+ (1,0) [0|1] "" Vector__XXX
 SG_ KP2_SetMask19 : 18|1@1+ (1,0) [0|1] "" Vector__XXX
 SG_ KP2_SetMask20 : 19|1@1+ (1,0) [0|1] "" Vector__XXX
 SG_ KP2_SetMask21 : 20|1@1+ (1,0) [0|1] "" Vector__XXX
 SG_ KP2_SetVal01 : 24|1@1+ (1,0) [0|1] "" Vector__XXX
 SG_ KP2_SetVal02 : 25|1@1+ (1,0) [0|1] "" Vector__XXX
 SG_ KP2_SetVal03 : 26|1@1+ (1,0) [0|1] "" Vector__XXX
 SG_ KP2_SetVal04 : 27|1@1+ (1,0) [0|1] "" Vector__XXX
 SG_ KP2_SetVal05 : 28|1@1+ (1,0) [0|1] "" Vector__XXX
 SG_ KP2_SetVal06 : 29|1@1+ (1,0) [0|1] "" Vector__XXX
 SG_ KP2_SetVal07 : 30|1@1+ (1,0) [0|1] "" Vector__XXX
 SG_ KP2_SetVal08 : 31|1@1+ (1,0) [0|1] "" Vector__XXX
 SG_ KP2_SetVal09 : 32|1@1+ (1,0) [0|1] "" Vector__XXX
 SG_ KP2_SetVal10 : 33|1@1+ (1,0) [0|1] "" Vector__XXX
 SG_ KP2_SetVal11 : 34|1@1+ (1,0) [0|1] "" Vector__XXX
 SG_ KP2_SetVal12 : 35|1@1+ (1,0) [0|1] "" Vector__XXX
 SG_ KP2_SetVal13 : 36|1@1+ (1,0) [0|1] "" Vector__XXX
 SG_ KP2_SetVal14 : 37|1@1+ (1,0) [0|1] "" Vector__XXX
 SG_ KP2_SetVal15 : 38|1@1+ (1,0) [0|1] "" Vector__XXX
 SG_ KP2_SetVal16 : 39|1@1+ (1,0) [0|1] "" Vector__XXX
 SG_ KP2_SetVal17 : 40|1@1+ (1,0) [0|1] "" Vector__XXX
 SG_ KP2_SetVal18 : 41|1@1+ (1,0) [0|1] "" Vector__XXX
 SG_ KP2_SetVal19 : 42|1@1+ (1,0) [0|1] "" Vector__XXX
 SG_ KP2_SetVal20 : 43|1@1+ (1,0) [0|1] "" Vector__XXX
 SG_ KP2_SetVal21 : 44|1@1+ (1,0) [0|1] "" Vector__XXX

BO_ 873 KP2_CmdCtl: 5 ECU
 SG_ KP2_CtlOpcode : 0|8@1+ (1,0) [0|255] "" Vector__XXX
 SG_ KP2_CtlArg1 : 8|8@1+ (1,0) [0|255] "" Vector__XXX
 SG_ KP2_CtlArg2 : 16|8@1+ (1,0) [0|255] "" Vector__XXX
 SG_ KP2_CtlArg3 : 24|8@1+ (1,0) [0|255] "" Vector__XXX
 SG_ KP2_CtlArg4 : 32|8@1+ (1,0) [0|255] "" Vector__XXX

BO_ 880 KP3_Outputs: 8 RCM
 SG_ KP3_CH01_Out : 0|1@1+ (1,0) [0|1] "" Vector__XXX
 SG_ KP3_CH02_Out : 1|1@1+ (1,0) [0|1] "" Vector__XXX
 SG_ KP3_CH03_Out : 2|1@1+ (1,0) [0|1] "" Vector__XXX
 SG_ KP3_CH04_Out : 3|1@1+ (1,0) [0|1] "" Vector__XXX
 SG_ KP3_CH05_Out : 4|1@1+ (1,0) [0|1] "" Vector__XXX
 SG_ KP3_CH06_Out : 5|1@1+ (1,0) [0|1] "" Vector__XXX
 SG_ KP3_CH07_Out : 6|1@1+ (1,0) [0|1] "" Vector__XXX
 SG_ KP3_CH08_Out : 7|1@1+ (1,0) [0|1] "" Vector__XXX
 SG_ KP3_CH09_Out : 8|1@1+ (1,0) [0|1] "" Vector__XXX
 SG_ KP3_CH10_Out : 9|1@1+ (1,0) [0|1] "" Vector__XXX
 SG_ KP3_CH11_Out : 10|1@1+ (1,0) [0|1] "" Vector__XXX
 SG_ KP3_CH12_Out : 11|1@1+ (1,0) [0|1] "" Vector__XXX
 SG_ KP3_CH13_Out : 12|1@1+ (1,0) [0|1] "" Vector__XXX
 SG_ KP3_CH14_Out : 13|1@1+ (1,0) [0|1] "" Vector__XXX
 SG_ KP3_CH15_Out : 14|1@1+ (1,0) [0|1] "" Vector__XXX
 SG_ KP3_CH16_Out : 15|1@1+ (1,0) [0|1] "" Vector__XXX
 SG_ KP3_CH17_Out : 16|1@1+ (1,0) [0|1] "" Vector__XXX
 SG_ KP3_CH18_Out : 17|1@1+ (1,0) [0|1] "" Vector__XXX
 SG_ KP3_CH19_Out : 18|1@1+ (1,0) [0|1] "" Vector__XXX
 SG_ KP3_CH20_Out : 19|1@1+ (1,0) [0|1] "" Vector__XXX
 SG_ KP3_CH21_Out : 20|1@1+ (1,0) [0|1] "" Vector__XXX
 SG_ KP3_OutputsEnabled : 24|1@1+ (1,0) [0|1] "" Vector__XXX
 SG_ KP3_Failsafe : 25|1@1+ (1,0) [0|1] "" Vector__XXX
 SG_ KP3_AnyFault : 26|1@1+ (1,0) [0|1] "" Vector__XXX
 SG_ KP3_ImuOk : 27|1@1+ (1,0) [0|1] "" Vector__XXX
 SG_ KP3_EepromOk : 28|1@1+ (1,0) [0|1] "" Vector__XXX
 SG_ KP3_RoleKeypad : 29|1@1+ (1,0) [0|1] "" Vector__XXX
 SG_ KP3_IgnitionOn : 30|1@1+ (1,0) [0|1] "" Vector__XXX
 SG_ KP3_Forced500k : 31|1@1+ (1,0) [0|1] "" Vector__XXX
 SG_ KP3_UptimeSec : 32|16@1+ (1,0) [0|65535] "s" Vector__XXX
 SG_ KP3_NodeId : 48|8@1+ (1,0) [0|7] "" Vector__XXX
 SG_ KP3_Seq : 56|8@1+ (1,0) [0|255] "" Vector__XXX

BO_ 881 KP3_Inputs: 8 RCM
 SG_ KP3_CH01_In : 0|1@1+ (1,0) [0|1] "" Vector__XXX
 SG_ KP3_CH02_In : 1|1@1+ (1,0) [0|1] "" Vector__XXX
 SG_ KP3_CH03_In : 2|1@1+ (1,0) [0|1] "" Vector__XXX
 SG_ KP3_CH04_In : 3|1@1+ (1,0) [0|1] "" Vector__XXX
 SG_ KP3_CH05_In : 4|1@1+ (1,0) [0|1] "" Vector__XXX
 SG_ KP3_CH06_In : 5|1@1+ (1,0) [0|1] "" Vector__XXX
 SG_ KP3_CH07_In : 6|1@1+ (1,0) [0|1] "" Vector__XXX
 SG_ KP3_CH08_In : 7|1@1+ (1,0) [0|1] "" Vector__XXX
 SG_ KP3_CH09_In : 8|1@1+ (1,0) [0|1] "" Vector__XXX
 SG_ KP3_CH10_In : 9|1@1+ (1,0) [0|1] "" Vector__XXX
 SG_ KP3_CH11_In : 10|1@1+ (1,0) [0|1] "" Vector__XXX
 SG_ KP3_CH12_In : 11|1@1+ (1,0) [0|1] "" Vector__XXX
 SG_ KP3_CH13_In : 12|1@1+ (1,0) [0|1] "" Vector__XXX
 SG_ KP3_CH14_In : 13|1@1+ (1,0) [0|1] "" Vector__XXX
 SG_ KP3_CH15_In : 14|1@1+ (1,0) [0|1] "" Vector__XXX
 SG_ KP3_CH16_In : 15|1@1+ (1,0) [0|1] "" Vector__XXX
 SG_ KP3_CH17_In : 16|1@1+ (1,0) [0|1] "" Vector__XXX
 SG_ KP3_CH18_In : 17|1@1+ (1,0) [0|1] "" Vector__XXX
 SG_ KP3_CH19_In : 18|1@1+ (1,0) [0|1] "" Vector__XXX
 SG_ KP3_CH20_In : 19|1@1+ (1,0) [0|1] "" Vector__XXX
 SG_ KP3_CH21_In : 20|1@1+ (1,0) [0|1] "" Vector__XXX
 SG_ KP3_Aux1 : 24|1@1+ (1,0) [0|1] "" Vector__XXX
 SG_ KP3_Aux2 : 25|1@1+ (1,0) [0|1] "" Vector__XXX
 SG_ KP3_Aux3 : 26|1@1+ (1,0) [0|1] "" Vector__XXX
 SG_ KP3_CH01_Sense : 32|1@1+ (1,0) [0|1] "" Vector__XXX
 SG_ KP3_CH02_Sense : 33|1@1+ (1,0) [0|1] "" Vector__XXX
 SG_ KP3_CH03_Sense : 34|1@1+ (1,0) [0|1] "" Vector__XXX
 SG_ KP3_CH04_Sense : 35|1@1+ (1,0) [0|1] "" Vector__XXX
 SG_ KP3_CH05_Sense : 36|1@1+ (1,0) [0|1] "" Vector__XXX
 SG_ KP3_CH06_Sense : 37|1@1+ (1,0) [0|1] "" Vector__XXX
 SG_ KP3_CH07_Sense : 38|1@1+ (1,0) [0|1] "" Vector__XXX
 SG_ KP3_CH08_Sense : 39|1@1+ (1,0) [0|1] "" Vector__XXX
 SG_ KP3_CH09_Sense : 40|1@1+ (1,0) [0|1] "" Vector__XXX
 SG_ KP3_CH10_Sense : 41|1@1+ (1,0) [0|1] "" Vector__XXX
 SG_ KP3_CH11_Sense : 42|1@1+ (1,0) [0|1] "" Vector__XXX
 SG_ KP3_CH12_Sense : 43|1@1+ (1,0) [0|1] "" Vector__XXX
 SG_ KP3_CH13_Sense : 44|1@1+ (1,0) [0|1] "" Vector__XXX
 SG_ KP3_CH14_Sense : 45|1@1+ (1,0) [0|1] "" Vector__XXX
 SG_ KP3_CH15_Sense : 46|1@1+ (1,0) [0|1] "" Vector__XXX
 SG_ KP3_CH16_Sense : 47|1@1+ (1,0) [0|1] "" Vector__XXX
 SG_ KP3_CH17_Sense : 48|1@1+ (1,0) [0|1] "" Vector__XXX
 SG_ KP3_CH18_Sense : 49|1@1+ (1,0) [0|1] "" Vector__XXX
 SG_ KP3_CH19_Sense : 50|1@1+ (1,0) [0|1] "" Vector__XXX
 SG_ KP3_CH20_Sense : 51|1@1+ (1,0) [0|1] "" Vector__XXX
 SG_ KP3_CH21_Sense : 52|1@1+ (1,0) [0|1] "" Vector__XXX
 SG_ KP3_InSeq : 56|8@1+ (1,0) [0|255] "" Vector__XXX

BO_ 882 KP3_Faults: 8 RCM
 SG_ KP3_CH01_Open : 0|1@1+ (1,0) [0|1] "" Vector__XXX
 SG_ KP3_CH02_Open : 1|1@1+ (1,0) [0|1] "" Vector__XXX
 SG_ KP3_CH03_Open : 2|1@1+ (1,0) [0|1] "" Vector__XXX
 SG_ KP3_CH04_Open : 3|1@1+ (1,0) [0|1] "" Vector__XXX
 SG_ KP3_CH05_Open : 4|1@1+ (1,0) [0|1] "" Vector__XXX
 SG_ KP3_CH06_Open : 5|1@1+ (1,0) [0|1] "" Vector__XXX
 SG_ KP3_CH07_Open : 6|1@1+ (1,0) [0|1] "" Vector__XXX
 SG_ KP3_CH08_Open : 7|1@1+ (1,0) [0|1] "" Vector__XXX
 SG_ KP3_CH09_Open : 8|1@1+ (1,0) [0|1] "" Vector__XXX
 SG_ KP3_CH10_Open : 9|1@1+ (1,0) [0|1] "" Vector__XXX
 SG_ KP3_CH11_Open : 10|1@1+ (1,0) [0|1] "" Vector__XXX
 SG_ KP3_CH12_Open : 11|1@1+ (1,0) [0|1] "" Vector__XXX
 SG_ KP3_CH13_Open : 12|1@1+ (1,0) [0|1] "" Vector__XXX
 SG_ KP3_CH14_Open : 13|1@1+ (1,0) [0|1] "" Vector__XXX
 SG_ KP3_CH15_Open : 14|1@1+ (1,0) [0|1] "" Vector__XXX
 SG_ KP3_CH16_Open : 15|1@1+ (1,0) [0|1] "" Vector__XXX
 SG_ KP3_CH17_Open : 16|1@1+ (1,0) [0|1] "" Vector__XXX
 SG_ KP3_CH18_Open : 17|1@1+ (1,0) [0|1] "" Vector__XXX
 SG_ KP3_CH19_Open : 18|1@1+ (1,0) [0|1] "" Vector__XXX
 SG_ KP3_CH20_Open : 19|1@1+ (1,0) [0|1] "" Vector__XXX
 SG_ KP3_CH21_Open : 20|1@1+ (1,0) [0|1] "" Vector__XXX
 SG_ KP3_CH01_Short : 24|1@1+ (1,0) [0|1] "" Vector__XXX
 SG_ KP3_CH02_Short : 25|1@1+ (1,0) [0|1] "" Vector__XXX
 SG_ KP3_CH03_Short : 26|1@1+ (1,0) [0|1] "" Vector__XXX
 SG_ KP3_CH04_Short : 27|1@1+ (1,0) [0|1] "" Vector__XXX
 SG_ KP3_CH05_Short : 28|1@1+ (1,0) [0|1] "" Vector__XXX
 SG_ KP3_CH06_Short : 29|1@1+ (1,0) [0|1] "" Vector__XXX
 SG_ KP3_CH07_Short : 30|1@1+ (1,0) [0|1] "" Vector__XXX
 SG_ KP3_CH08_Short : 31|1@1+ (1,0) [0|1] "" Vector__XXX
 SG_ KP3_CH09_Short : 32|1@1+ (1,0) [0|1] "" Vector__XXX
 SG_ KP3_CH10_Short : 33|1@1+ (1,0) [0|1] "" Vector__XXX
 SG_ KP3_CH11_Short : 34|1@1+ (1,0) [0|1] "" Vector__XXX
 SG_ KP3_CH12_Short : 35|1@1+ (1,0) [0|1] "" Vector__XXX
 SG_ KP3_CH13_Short : 36|1@1+ (1,0) [0|1] "" Vector__XXX
 SG_ KP3_CH14_Short : 37|1@1+ (1,0) [0|1] "" Vector__XXX
 SG_ KP3_CH15_Short : 38|1@1+ (1,0) [0|1] "" Vector__XXX
 SG_ KP3_CH16_Short : 39|1@1+ (1,0) [0|1] "" Vector__XXX
 SG_ KP3_CH17_Short : 40|1@1+ (1,0) [0|1] "" Vector__XXX
 SG_ KP3_CH18_Short : 41|1@1+ (1,0) [0|1] "" Vector__XXX
 SG_ KP3_CH19_Short : 42|1@1+ (1,0) [0|1] "" Vector__XXX
 SG_ KP3_CH20_Short : 43|1@1+ (1,0) [0|1] "" Vector__XXX
 SG_ KP3_CH21_Short : 44|1@1+ (1,0) [0|1] "" Vector__XXX
 SG_ KP3_FaultSeq : 56|8@1+ (1,0) [0|255] "" Vector__XXX

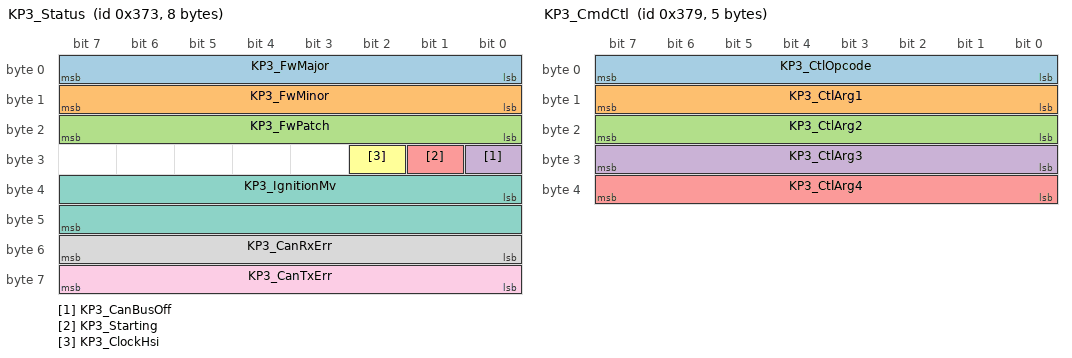
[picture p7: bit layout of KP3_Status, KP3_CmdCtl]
BO_ 883 KP3_Status: 8 RCM
 SG_ KP3_FwMajor : 0|8@1+ (1,0) [0|255] "" Vector__XXX
 SG_ KP3_FwMinor : 8|8@1+ (1,0) [0|255] "" Vector__XXX
 SG_ KP3_FwPatch : 16|8@1+ (1,0) [0|255] "" Vector__XXX
 SG_ KP3_CanBusOff : 24|1@1+ (1,0) [0|1] "" Vector__XXX
 SG_ KP3_Starting : 25|1@1+ (1,0) [0|1] "" Vector__XXX
 SG_ KP3_ClockHsi : 26|1@1+ (1,0) [0|1] "" Vector__XXX
 SG_ KP3_IgnitionMv : 32|16@1+ (1,0) [0|65535] "mV" Vector__XXX
 SG_ KP3_CanRxErr : 48|8@1+ (1,0) [0|255] "" Vector__XXX
 SG_ KP3_CanTxErr : 56|8@1+ (1,0) [0|255] "" Vector__XXX

BO_ 888 KP3_CmdSet: 6 ECU
 SG_ KP3_SetMask01 : 0|1@1+ (1,0) [0|1] "" Vector__XXX
 SG_ KP3_SetMask02 : 1|1@1+ (1,0) [0|1] "" Vector__XXX
 SG_ KP3_SetMask03 : 2|1@1+ (1,0) [0|1] "" Vector__XXX
 SG_ KP3_SetMask04 : 3|1@1+ (1,0) [0|1] "" Vector__XXX
 SG_ KP3_SetMask05 : 4|1@1+ (1,0) [0|1] "" Vector__XXX
 SG_ KP3_SetMask06 : 5|1@1+ (1,0) [0|1] "" Vector__XXX
 SG_ KP3_SetMask07 : 6|1@1+ (1,0) [0|1] "" Vector__XXX
 SG_ KP3_SetMask08 : 7|1@1+ (1,0) [0|1] "" Vector__XXX
 SG_ KP3_SetMask09 : 8|1@1+ (1,0) [0|1] "" Vector__XXX
 SG_ KP3_SetMask10 : 9|1@1+ (1,0) [0|1] "" Vector__XXX
 SG_ KP3_SetMask11 : 10|1@1+ (1,0) [0|1] "" Vector__XXX
 SG_ KP3_SetMask12 : 11|1@1+ (1,0) [0|1] "" Vector__XXX
 SG_ KP3_SetMask13 : 12|1@1+ (1,0) [0|1] "" Vector__XXX
 SG_ KP3_SetMask14 : 13|1@1+ (1,0) [0|1] "" Vector__XXX
 SG_ KP3_SetMask15 : 14|1@1+ (1,0) [0|1] "" Vector__XXX
 SG_ KP3_SetMask16 : 15|1@1+ (1,0) [0|1] "" Vector__XXX
 SG_ KP3_SetMask17 : 16|1@1+ (1,0) [0|1] "" Vector__XXX
 SG_ KP3_SetMask18 : 17|1@1+ (1,0) [0|1] "" Vector__XXX
 SG_ KP3_SetMask19 : 18|1@1+ (1,0) [0|1] "" Vector__XXX
 SG_ KP3_SetMask20 : 19|1@1+ (1,0) [0|1] "" Vector__XXX
 SG_ KP3_SetMask21 : 20|1@1+ (1,0) [0|1] "" Vector__XXX
 SG_ KP3_SetVal01 : 24|1@1+ (1,0) [0|1] "" Vector__XXX
 SG_ KP3_SetVal02 : 25|1@1+ (1,0) [0|1] "" Vector__XXX
 SG_ KP3_SetVal03 : 26|1@1+ (1,0) [0|1] "" Vector__XXX
 SG_ KP3_SetVal04 : 27|1@1+ (1,0) [0|1] "" Vector__XXX
 SG_ KP3_SetVal05 : 28|1@1+ (1,0) [0|1] "" Vector__XXX
 SG_ KP3_SetVal06 : 29|1@1+ (1,0) [0|1] "" Vector__XXX
 SG_ KP3_SetVal07 : 30|1@1+ (1,0) [0|1] "" Vector__XXX
 SG_ KP3_SetVal08 : 31|1@1+ (1,0) [0|1] "" Vector__XXX
 SG_ KP3_SetVal09 : 32|1@1+ (1,0) [0|1] "" Vector__XXX
 SG_ KP3_SetVal10 : 33|1@1+ (1,0) [0|1] "" Vector__XXX
 SG_ KP3_SetVal11 : 34|1@1+ (1,0) [0|1] "" Vector__XXX
 SG_ KP3_SetVal12 : 35|1@1+ (1,0) [0|1] "" Vector__XXX
 SG_ KP3_SetVal13 : 36|1@1+ (1,0) [0|1] "" Vector__XXX
 SG_ KP3_SetVal14 : 37|1@1+ (1,0) [0|1] "" Vector__XXX
 SG_ KP3_SetVal15 : 38|1@1+ (1,0) [0|1] "" Vector__XXX
 SG_ KP3_SetVal16 : 39|1@1+ (1,0) [0|1] "" Vector__XXX
 SG_ KP3_SetVal17 : 40|1@1+ (1,0) [0|1] "" Vector__XXX
 SG_ KP3_SetVal18 : 41|1@1+ (1,0) [0|1] "" Vector__XXX
 SG_ KP3_SetVal19 : 42|1@1+ (1,0) [0|1] "" Vector__XXX
 SG_ KP3_SetVal20 : 43|1@1+ (1,0) [0|1] "" Vector__XXX
 SG_ KP3_SetVal21 : 44|1@1+ (1,0) [0|1] "" Vector__XXX

BO_ 889 KP3_CmdCtl: 5 ECU
 SG_ KP3_CtlOpcode : 0|8@1+ (1,0) [0|255] "" Vector__XXX
 SG_ KP3_CtlArg1 : 8|8@1+ (1,0) [0|255] "" Vector__XXX
 SG_ KP3_CtlArg2 : 16|8@1+ (1,0) [0|255] "" Vector__XXX
 SG_ KP3_CtlArg3 : 24|8@1+ (1,0) [0|255] "" Vector__XXX
 SG_ KP3_CtlArg4 : 32|8@1+ (1,0) [0|255] "" Vector__XXX

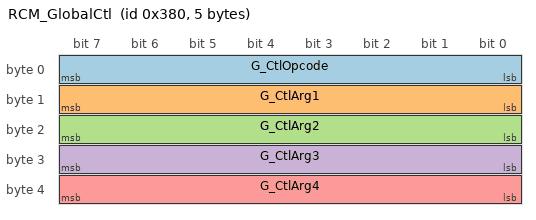
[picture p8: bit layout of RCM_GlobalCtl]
BO_ 896 RCM_GlobalCtl: 5 ECU
 SG_ G_CtlOpcode : 0|8@1+ (1,0) [0|255] "" Vector__XXX
 SG_ G_CtlArg1 : 8|8@1+ (1,0) [0|255] "" Vector__XXX
 SG_ G_CtlArg2 : 16|8@1+ (1,0) [0|255] "" Vector__XXX
 SG_ G_CtlArg3 : 24|8@1+ (1,0) [0|255] "" Vector__XXX
 SG_ G_CtlArg4 : 32|8@1+ (1,0) [0|255] "" Vector__XXX

BO_ 372 MM5_10_YawRate_AccY: 8 RCM
 SG_ YawRate : 0|16@1+ (0.005,-163.84) [-163.84|163.83] "deg/s" ECU
 SG_ AccelLateral : 32|16@1+ (0.0001274,-4.17464) [-4.17|4.17] "g" ECU

BO_ 376 MM5_10_RollRate_AccX: 8 RCM
 SG_ AccelLongitudinal : 32|16@1+ (0.0001274,-4.17464) [-4.17|4.17] "g" ECU

BO_ 380 MM5_10_AccZ: 8 RCM
 SG_ AccelVertical : 32|16@1+ (0.0001274,-4.17464) [-4.17|4.17] "g" ECU

CM_ BO_ 768 "RCM node 0 (relay module address 0) commanded output states";
CM_ BO_ 784 "RCM node 1 (relay module address 1) commanded output states";
CM_ BO_ 800 "RCM node 2 (relay module address 2) commanded output states";
CM_ BO_ 816 "RCM node 3 (relay module address 3) commanded output states";
CM_ BO_ 832 "RCM node 4 (keypad address 0) commanded output states";
CM_ BO_ 848 "RCM node 5 (keypad address 1) commanded output states";
CM_ BO_ 864 "RCM node 6 (keypad address 2) commanded output states";
CM_ BO_ 880 "RCM node 7 (keypad address 3) commanded output states";
CM_ BO_ 372 "Bosch MM5.10 emulation -- set imuType = IMU_MM5_10 in rusEFI and it decodes these with no further configuration";
CM_ BU_ RCM "CAN relay control module / keypad. Node id = DIP address, plus 4 when the role switch says keypad.";
